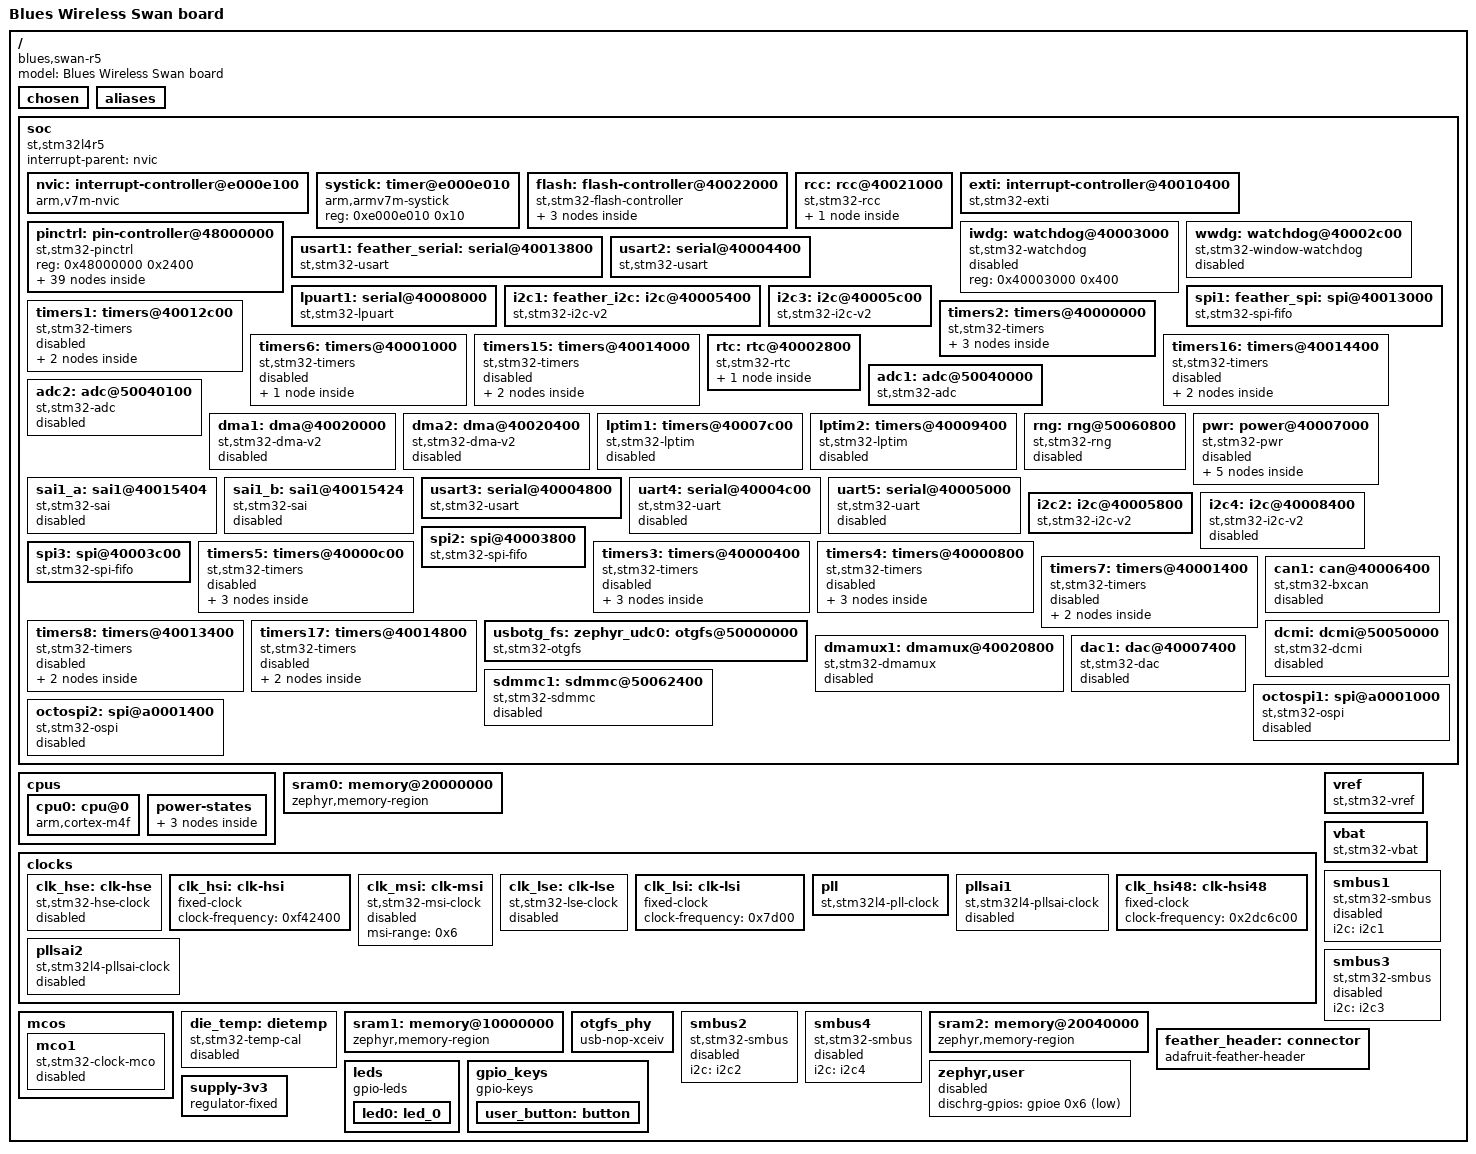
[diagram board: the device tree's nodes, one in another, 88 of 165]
/dts-v1/;

/* node '/' defined in zephyr/dts/common/skeleton.dtsi:9 */
/ {
	#address-cells = < 0x1 >;            /* in zephyr/dts/common/skeleton.dtsi:10 */
	#size-cells = < 0x1 >;               /* in zephyr/dts/common/skeleton.dtsi:11 */
	model = "Blues Wireless Swan board"; /* in zephyr/boards/blues/swan_r5/swan_r5.dts:14 */
	compatible = "blues,swan-r5";        /* in zephyr/boards/blues/swan_r5/swan_r5.dts:15 */

	/* node '/chosen' defined in zephyr/dts/common/skeleton.dtsi:13 */
	chosen {
		zephyr,entropy = &rng;            /* in zephyr/dts/arm/st/l4/stm32l4.dtsi:26 */
		zephyr,flash-controller = &flash; /* in zephyr/dts/arm/st/l4/stm32l4.dtsi:27 */
		zephyr,console = &lpuart1;        /* in zephyr/boards/blues/swan_r5/swan_r5.dts:18 */
		zephyr,shell-uart = &lpuart1;     /* in zephyr/boards/blues/swan_r5/swan_r5.dts:19 */
		zephyr,sram = &sram0;             /* in zephyr/boards/blues/swan_r5/swan_r5.dts:20 */
		zephyr,flash = &flash0;           /* in zephyr/boards/blues/swan_r5/swan_r5.dts:21 */
	};

	/* node '/aliases' defined in zephyr/dts/common/skeleton.dtsi:15 */
	aliases {
		led0 = &led0;         /* in zephyr/boards/blues/swan_r5/swan_r5.dts:57 */
		sw0 = &user_button;   /* in zephyr/boards/blues/swan_r5/swan_r5.dts:58 */
		volt-sensor0 = &vref; /* in zephyr/boards/blues/swan_r5/swan_r5.dts:59 */
		volt-sensor1 = &vbat; /* in zephyr/boards/blues/swan_r5/swan_r5.dts:60 */
	};

	/* node '/soc' defined in zephyr/dts/arm/armv7-m.dtsi:6 */
	soc {
		#address-cells = < 0x1 >;     /* in zephyr/dts/arm/armv7-m.dtsi:7 */
		#size-cells = < 0x1 >;        /* in zephyr/dts/arm/armv7-m.dtsi:8 */
		interrupt-parent = < &nvic >; /* in zephyr/dts/arm/armv7-m.dtsi:10 */
		ranges;                       /* in zephyr/dts/arm/armv7-m.dtsi:11 */
		compatible = "st,stm32l4r5",
		             "st,stm32l4",
		             "simple-bus";    /* in zephyr/dts/arm/st/l4/stm32l4r5.dtsi:29 */

		/* node '/soc/interrupt-controller@e000e100' defined in zephyr/dts/arm/armv7-m.dtsi:13 */
		nvic: interrupt-controller@e000e100 {
			#address-cells = < 0x1 >;            /* in zephyr/dts/arm/armv7-m.dtsi:14 */
			compatible = "arm,v7m-nvic";         /* in zephyr/dts/arm/armv7-m.dtsi:15 */
			reg = < 0xe000e100 0xc00 >;          /* in zephyr/dts/arm/armv7-m.dtsi:16 */
			interrupt-controller;                /* in zephyr/dts/arm/armv7-m.dtsi:17 */
			#interrupt-cells = < 0x2 >;          /* in zephyr/dts/arm/armv7-m.dtsi:18 */
			arm,num-irq-priority-bits = < 0x4 >; /* in zephyr/dts/arm/st/l4/stm32l4.dtsi:596 */
			phandle = < 0x1 >;                   /* in zephyr/dts/arm/armv7-m.dtsi:10 */
		};

		/* node '/soc/timer@e000e010' defined in zephyr/dts/arm/armv7-m.dtsi:21 */
		systick: timer@e000e010 {
			compatible = "arm,armv7m-systick"; /* in zephyr/dts/arm/armv7-m.dtsi:22 */
			reg = < 0xe000e010 0x10 >;         /* in zephyr/dts/arm/armv7-m.dtsi:23 */
		};

		/* node '/soc/flash-controller@40022000' defined in zephyr/dts/arm/st/l4/stm32l4.dtsi:127 */
		flash: flash-controller@40022000 {
			compatible = "st,stm32-flash-controller",
			             "st,stm32l4-flash-controller"; /* in zephyr/dts/arm/st/l4/stm32l4.dtsi:128 */
			reg = < 0x40022000 0x400 >;                 /* in zephyr/dts/arm/st/l4/stm32l4.dtsi:129 */
			interrupts = < 0x4 0x0 >;                   /* in zephyr/dts/arm/st/l4/stm32l4.dtsi:130 */
			clocks = < &rcc 0x48 0x100 >;               /* in zephyr/dts/arm/st/l4/stm32l4.dtsi:131 */
			#address-cells = < 0x1 >;                   /* in zephyr/dts/arm/st/l4/stm32l4.dtsi:133 */
			#size-cells = < 0x1 >;                      /* in zephyr/dts/arm/st/l4/stm32l4.dtsi:134 */

			/* node '/soc/flash-controller@40022000/flash@8000000' defined in zephyr/dts/arm/st/l4/stm32l4.dtsi:136 */
			flash0: flash@8000000 {
				compatible = "st,stm32-nv-flash",
				             "soc-nv-flash";      /* in zephyr/dts/arm/st/l4/stm32l4.dtsi:137 */
				write-block-size = < 0x8 >;       /* in zephyr/dts/arm/st/l4/stm32l4.dtsi:139 */
				max-erase-time = < 0x19 >;        /* in zephyr/dts/arm/st/l4/stm32l4.dtsi:142 */
				erase-block-size = < 0x1000 >;    /* in zephyr/dts/arm/st/l4/stm32l4p5.dtsi:53 */
				reg = < 0x8000000 0x200000 >;     /* in zephyr/dts/arm/st/l4/stm32l4r5Xi.dtsi:14 */

				/* node '/soc/flash-controller@40022000/flash@8000000/partitions' defined in zephyr/boards/blues/swan_r5/swan_r5.dts:185 */
				partitions {
					compatible = "fixed-partitions"; /* in zephyr/boards/blues/swan_r5/swan_r5.dts:186 */
					#address-cells = < 0x1 >;        /* in zephyr/boards/blues/swan_r5/swan_r5.dts:187 */
					#size-cells = < 0x1 >;           /* in zephyr/boards/blues/swan_r5/swan_r5.dts:188 */

					/* node '/soc/flash-controller@40022000/flash@8000000/partitions/partition@1FB000' defined in zephyr/boards/blues/swan_r5/swan_r5.dts:191 */
					storage_partition: partition@1FB000 {
						label = "storage";         /* in zephyr/boards/blues/swan_r5/swan_r5.dts:192 */
						reg = < 0x1fb000 0x4000 >; /* in zephyr/boards/blues/swan_r5/swan_r5.dts:193 */
					};
				};
			};
		};

		/* node '/soc/rcc@40021000' defined in zephyr/dts/arm/st/l4/stm32l4.dtsi:146 */
		rcc: rcc@40021000 {
			compatible = "st,stm32-rcc";     /* in zephyr/dts/arm/st/l4/stm32l4.dtsi:147 */
			#clock-cells = < 0x2 >;          /* in zephyr/dts/arm/st/l4/stm32l4.dtsi:148 */
			reg = < 0x40021000 0x400 >;      /* in zephyr/dts/arm/st/l4/stm32l4.dtsi:149 */
			undershoot-prevention;           /* in zephyr/dts/arm/st/l4/stm32l4p5.dtsi:58 */
			clocks = < &pll >;               /* in zephyr/boards/blues/swan_r5/swan_r5.dts:87 */
			clock-frequency = < 0x4c4b400 >; /* in zephyr/boards/blues/swan_r5/swan_r5.dts:88 */
			ahb-prescaler = < 0x1 >;         /* in zephyr/boards/blues/swan_r5/swan_r5.dts:89 */
			apb1-prescaler = < 0x1 >;        /* in zephyr/boards/blues/swan_r5/swan_r5.dts:90 */
			apb2-prescaler = < 0x1 >;        /* in zephyr/boards/blues/swan_r5/swan_r5.dts:91 */
			phandle = < 0x2 >;               /* in zephyr/dts/arm/st/l4/stm32l4.dtsi:131 */

			/* node '/soc/rcc@40021000/reset-controller' defined in zephyr/dts/arm/st/l4/stm32l4.dtsi:151 */
			rctl: reset-controller {
				compatible = "st,stm32-rcc-rctl"; /* in zephyr/dts/arm/st/l4/stm32l4.dtsi:152 */
				#reset-cells = < 0x1 >;           /* in zephyr/dts/arm/st/l4/stm32l4.dtsi:153 */
				phandle = < 0x4 >;                /* in zephyr/dts/arm/st/l4/stm32l4.dtsi:230 */
			};
		};

		/* node '/soc/interrupt-controller@40010400' defined in zephyr/dts/arm/st/l4/stm32l4.dtsi:157 */
		exti: interrupt-controller@40010400 {
			compatible = "st,stm32-exti";  /* in zephyr/dts/arm/st/l4/stm32l4.dtsi:158 */
			interrupt-controller;          /* in zephyr/dts/arm/st/l4/stm32l4.dtsi:159 */
			#interrupt-cells = < 0x1 >;    /* in zephyr/dts/arm/st/l4/stm32l4.dtsi:160 */
			#address-cells = < 0x0 >;      /* in zephyr/dts/arm/st/l4/stm32l4.dtsi:161 */
			reg = < 0x40010400 0x400 >;    /* in zephyr/dts/arm/st/l4/stm32l4.dtsi:162 */
			clocks = < &rcc 0x60 0x1 >;    /* in zephyr/dts/arm/st/l4/stm32l4.dtsi:163 */
			num-lines = < 0x40 >;          /* in zephyr/dts/arm/st/l4/stm32l4.dtsi:164 */
			interrupts = < 0x6 0x0 >,
			             < 0x7 0x0 >,
			             < 0x8 0x0 >,
			             < 0x9 0x0 >,
			             < 0xa 0x0 >,
			             < 0x17 0x0 >,
			             < 0x28 0x0 >;     /* in zephyr/dts/arm/st/l4/stm32l4.dtsi:165 */
			interrupt-names = "line0",
			                  "line1",
			                  "line2",
			                  "line3",
			                  "line4",
			                  "line5-9",
			                  "line10-15"; /* in zephyr/dts/arm/st/l4/stm32l4.dtsi:167 */
			line-ranges = < 0x0 0x1 >,
			              < 0x1 0x1 >,
			              < 0x2 0x1 >,
			              < 0x3 0x1 >,
			              < 0x4 0x1 >,
			              < 0x5 0x5 >,
			              < 0xa 0x6 >;     /* in zephyr/dts/arm/st/l4/stm32l4.dtsi:169 */
		};

		/* node '/soc/pin-controller@48000000' defined in zephyr/dts/arm/st/l4/stm32l4.dtsi:173 */
		pinctrl: pin-controller@48000000 {
			compatible = "st,stm32-pinctrl"; /* in zephyr/dts/arm/st/l4/stm32l4.dtsi:174 */
			#address-cells = < 0x1 >;        /* in zephyr/dts/arm/st/l4/stm32l4.dtsi:175 */
			#size-cells = < 0x1 >;           /* in zephyr/dts/arm/st/l4/stm32l4.dtsi:176 */
			reg = < 0x48000000 0x2400 >;     /* in zephyr/dts/arm/st/l4/stm32l4p5.dtsi:67 */

			/* node '/soc/pin-controller@48000000/gpio@48000000' defined in zephyr/dts/arm/st/l4/stm32l4.dtsi:179 */
			gpioa: gpio@48000000 {
				compatible = "st,stm32-gpio"; /* in zephyr/dts/arm/st/l4/stm32l4.dtsi:180 */
				gpio-controller;              /* in zephyr/dts/arm/st/l4/stm32l4.dtsi:181 */
				#gpio-cells = < 0x2 >;        /* in zephyr/dts/arm/st/l4/stm32l4.dtsi:182 */
				reg = < 0x48000000 0x400 >;   /* in zephyr/dts/arm/st/l4/stm32l4.dtsi:183 */
				clocks = < &rcc 0x4c 0x1 >;   /* in zephyr/dts/arm/st/l4/stm32l4.dtsi:184 */
				phandle = < 0x12 >;           /* in zephyr/boards/blues/swan_r5/swan_r5.dts:143 */
			};

			/* node '/soc/pin-controller@48000000/gpio@48000400' defined in zephyr/dts/arm/st/l4/stm32l4.dtsi:187 */
			gpiob: gpio@48000400 {
				compatible = "st,stm32-gpio"; /* in zephyr/dts/arm/st/l4/stm32l4.dtsi:188 */
				gpio-controller;              /* in zephyr/dts/arm/st/l4/stm32l4.dtsi:189 */
				#gpio-cells = < 0x2 >;        /* in zephyr/dts/arm/st/l4/stm32l4.dtsi:190 */
				reg = < 0x48000400 0x400 >;   /* in zephyr/dts/arm/st/l4/stm32l4.dtsi:191 */
				clocks = < &rcc 0x4c 0x2 >;   /* in zephyr/dts/arm/st/l4/stm32l4.dtsi:192 */
				phandle = < 0x32 >;           /* in zephyr/boards/blues/swan_r5/feather_connector.dtsi:13 */
			};

			/* node '/soc/pin-controller@48000000/gpio@48000800' defined in zephyr/dts/arm/st/l4/stm32l4.dtsi:195 */
			gpioc: gpio@48000800 {
				compatible = "st,stm32-gpio"; /* in zephyr/dts/arm/st/l4/stm32l4.dtsi:196 */
				gpio-controller;              /* in zephyr/dts/arm/st/l4/stm32l4.dtsi:197 */
				#gpio-cells = < 0x2 >;        /* in zephyr/dts/arm/st/l4/stm32l4.dtsi:198 */
				reg = < 0x48000800 0x400 >;   /* in zephyr/dts/arm/st/l4/stm32l4.dtsi:199 */
				clocks = < &rcc 0x4c 0x4 >;   /* in zephyr/dts/arm/st/l4/stm32l4.dtsi:200 */
				phandle = < 0x15 >;           /* in zephyr/dts/arm/st/l4/stm32l4r5Xi.dtsi:26 */
			};

			/* node '/soc/pin-controller@48000000/gpio@48001c00' defined in zephyr/dts/arm/st/l4/stm32l4.dtsi:203 */
			gpioh: gpio@48001c00 {
				compatible = "st,stm32-gpio"; /* in zephyr/dts/arm/st/l4/stm32l4.dtsi:204 */
				gpio-controller;              /* in zephyr/dts/arm/st/l4/stm32l4.dtsi:205 */
				#gpio-cells = < 0x2 >;        /* in zephyr/dts/arm/st/l4/stm32l4.dtsi:206 */
				reg = < 0x48001c00 0x400 >;   /* in zephyr/dts/arm/st/l4/stm32l4.dtsi:207 */
				clocks = < &rcc 0x4c 0x80 >;  /* in zephyr/dts/arm/st/l4/stm32l4.dtsi:208 */
			};

			/* node '/soc/pin-controller@48000000/gpio@48000c00' defined in zephyr/dts/arm/st/l4/stm32l4p5.dtsi:69 */
			gpiod: gpio@48000c00 {
				compatible = "st,stm32-gpio"; /* in zephyr/dts/arm/st/l4/stm32l4p5.dtsi:70 */
				gpio-controller;              /* in zephyr/dts/arm/st/l4/stm32l4p5.dtsi:71 */
				#gpio-cells = < 0x2 >;        /* in zephyr/dts/arm/st/l4/stm32l4p5.dtsi:72 */
				reg = < 0x48000c00 0x400 >;   /* in zephyr/dts/arm/st/l4/stm32l4p5.dtsi:73 */
				clocks = < &rcc 0x4c 0x8 >;   /* in zephyr/dts/arm/st/l4/stm32l4p5.dtsi:74 */
				phandle = < 0x33 >;           /* in zephyr/boards/blues/swan_r5/feather_connector.dtsi:13 */
			};

			/* node '/soc/pin-controller@48000000/gpio@48001000' defined in zephyr/dts/arm/st/l4/stm32l4p5.dtsi:77 */
			gpioe: gpio@48001000 {
				compatible = "st,stm32-gpio"; /* in zephyr/dts/arm/st/l4/stm32l4p5.dtsi:78 */
				gpio-controller;              /* in zephyr/dts/arm/st/l4/stm32l4p5.dtsi:79 */
				#gpio-cells = < 0x2 >;        /* in zephyr/dts/arm/st/l4/stm32l4p5.dtsi:80 */
				reg = < 0x48001000 0x400 >;   /* in zephyr/dts/arm/st/l4/stm32l4p5.dtsi:81 */
				clocks = < &rcc 0x4c 0x10 >;  /* in zephyr/dts/arm/st/l4/stm32l4p5.dtsi:82 */
				phandle = < 0x16 >;           /* in zephyr/dts/arm/st/l4/stm32l4r5Xi.dtsi:30 */
			};

			/* node '/soc/pin-controller@48000000/gpio@48001400' defined in zephyr/dts/arm/st/l4/stm32l4p5.dtsi:85 */
			gpiof: gpio@48001400 {
				compatible = "st,stm32-gpio"; /* in zephyr/dts/arm/st/l4/stm32l4p5.dtsi:86 */
				gpio-controller;              /* in zephyr/dts/arm/st/l4/stm32l4p5.dtsi:87 */
				#gpio-cells = < 0x2 >;        /* in zephyr/dts/arm/st/l4/stm32l4p5.dtsi:88 */
				reg = < 0x48001400 0x400 >;   /* in zephyr/dts/arm/st/l4/stm32l4p5.dtsi:89 */
				clocks = < &rcc 0x4c 0x20 >;  /* in zephyr/dts/arm/st/l4/stm32l4p5.dtsi:90 */
			};

			/* node '/soc/pin-controller@48000000/gpio@48001800' defined in zephyr/dts/arm/st/l4/stm32l4p5.dtsi:93 */
			gpiog: gpio@48001800 {
				compatible = "st,stm32-gpio"; /* in zephyr/dts/arm/st/l4/stm32l4p5.dtsi:94 */
				gpio-controller;              /* in zephyr/dts/arm/st/l4/stm32l4p5.dtsi:95 */
				#gpio-cells = < 0x2 >;        /* in zephyr/dts/arm/st/l4/stm32l4p5.dtsi:96 */
				reg = < 0x48001800 0x400 >;   /* in zephyr/dts/arm/st/l4/stm32l4p5.dtsi:97 */
				clocks = < &rcc 0x4c 0x40 >;  /* in zephyr/dts/arm/st/l4/stm32l4p5.dtsi:98 */
			};

			/* node '/soc/pin-controller@48000000/gpio@48002000' defined in zephyr/dts/arm/st/l4/stm32l4p5.dtsi:101 */
			gpioi: gpio@48002000 {
				compatible = "st,stm32-gpio"; /* in zephyr/dts/arm/st/l4/stm32l4p5.dtsi:102 */
				gpio-controller;              /* in zephyr/dts/arm/st/l4/stm32l4p5.dtsi:103 */
				#gpio-cells = < 0x2 >;        /* in zephyr/dts/arm/st/l4/stm32l4p5.dtsi:104 */
				reg = < 0x48002000 0x400 >;   /* in zephyr/dts/arm/st/l4/stm32l4p5.dtsi:105 */
				clocks = < &rcc 0x4c 0x100 >; /* in zephyr/dts/arm/st/l4/stm32l4p5.dtsi:106 */
			};

			/* node '/soc/pin-controller@48000000/adc1_in6_pa1' defined in modules/hal/stm32/dts/st/l4/stm32l4r5z(g-i)yx-pinctrl.dtsi:19 */
			adc1_in6_pa1: adc1_in6_pa1 {
				pinmux = < 0x30 >;  /* in modules/hal/stm32/dts/st/l4/stm32l4r5z(g-i)yx-pinctrl.dtsi:20 */
				phandle = < 0x14 >; /* in zephyr/boards/blues/swan_r5/swan_r5.dts:199 */
			};

			/* node '/soc/pin-controller@48000000/i2c1_scl_pb6' defined in modules/hal/stm32/dts/st/l4/stm32l4r5z(g-i)yx-pinctrl.dtsi:1299 */
			i2c1_scl_pb6: i2c1_scl_pb6 {
				pinmux = < 0x2c4 >; /* in modules/hal/stm32/dts/st/l4/stm32l4r5z(g-i)yx-pinctrl.dtsi:1300 */
				bias-pull-up;       /* in modules/hal/stm32/dts/st/l4/stm32l4r5z(g-i)yx-pinctrl.dtsi:1301 */
				drive-open-drain;   /* in modules/hal/stm32/dts/st/l4/stm32l4r5z(g-i)yx-pinctrl.dtsi:1302 */
				phandle = < 0xb >;  /* in zephyr/boards/blues/swan_r5/swan_r5.dts:123 */
			};

			/* node '/soc/pin-controller@48000000/i2c2_scl_pf1' defined in modules/hal/stm32/dts/st/l4/stm32l4r5z(g-i)yx-pinctrl.dtsi:1323 */
			i2c2_scl_pf1: i2c2_scl_pf1 {
				pinmux = < 0xa24 >; /* in modules/hal/stm32/dts/st/l4/stm32l4r5z(g-i)yx-pinctrl.dtsi:1324 */
				bias-pull-up;       /* in modules/hal/stm32/dts/st/l4/stm32l4r5z(g-i)yx-pinctrl.dtsi:1325 */
				drive-open-drain;   /* in modules/hal/stm32/dts/st/l4/stm32l4r5z(g-i)yx-pinctrl.dtsi:1326 */
				phandle = < 0x1a >; /* in zephyr/boards/blues/swan_r5/swan_r5.dts:129 */
			};

			/* node '/soc/pin-controller@48000000/i2c3_scl_pc0' defined in modules/hal/stm32/dts/st/l4/stm32l4r5z(g-i)yx-pinctrl.dtsi:1335 */
			i2c3_scl_pc0: i2c3_scl_pc0 {
				pinmux = < 0x404 >; /* in modules/hal/stm32/dts/st/l4/stm32l4r5z(g-i)yx-pinctrl.dtsi:1336 */
				bias-pull-up;       /* in modules/hal/stm32/dts/st/l4/stm32l4r5z(g-i)yx-pinctrl.dtsi:1337 */
				drive-open-drain;   /* in modules/hal/stm32/dts/st/l4/stm32l4r5z(g-i)yx-pinctrl.dtsi:1338 */
				phandle = < 0xd >;  /* in zephyr/boards/blues/swan_r5/swan_r5.dts:135 */
			};

			/* node '/soc/pin-controller@48000000/i2c1_sda_pb7' defined in modules/hal/stm32/dts/st/l4/stm32l4r5z(g-i)yx-pinctrl.dtsi:1373 */
			i2c1_sda_pb7: i2c1_sda_pb7 {
				pinmux = < 0x2e4 >; /* in modules/hal/stm32/dts/st/l4/stm32l4r5z(g-i)yx-pinctrl.dtsi:1374 */
				bias-pull-up;       /* in modules/hal/stm32/dts/st/l4/stm32l4r5z(g-i)yx-pinctrl.dtsi:1375 */
				drive-open-drain;   /* in modules/hal/stm32/dts/st/l4/stm32l4r5z(g-i)yx-pinctrl.dtsi:1376 */
				phandle = < 0xc >;  /* in zephyr/boards/blues/swan_r5/swan_r5.dts:123 */
			};

			/* node '/soc/pin-controller@48000000/i2c2_sda_pf0' defined in modules/hal/stm32/dts/st/l4/stm32l4r5z(g-i)yx-pinctrl.dtsi:1403 */
			i2c2_sda_pf0: i2c2_sda_pf0 {
				pinmux = < 0xa04 >; /* in modules/hal/stm32/dts/st/l4/stm32l4r5z(g-i)yx-pinctrl.dtsi:1404 */
				bias-pull-up;       /* in modules/hal/stm32/dts/st/l4/stm32l4r5z(g-i)yx-pinctrl.dtsi:1405 */
				drive-open-drain;   /* in modules/hal/stm32/dts/st/l4/stm32l4r5z(g-i)yx-pinctrl.dtsi:1406 */
				phandle = < 0x1b >; /* in zephyr/boards/blues/swan_r5/swan_r5.dts:129 */
			};

			/* node '/soc/pin-controller@48000000/i2c3_sda_pc9' defined in modules/hal/stm32/dts/st/l4/stm32l4r5z(g-i)yx-pinctrl.dtsi:1421 */
			i2c3_sda_pc9: i2c3_sda_pc9 {
				pinmux = < 0x526 >; /* in modules/hal/stm32/dts/st/l4/stm32l4r5z(g-i)yx-pinctrl.dtsi:1422 */
				bias-pull-up;       /* in modules/hal/stm32/dts/st/l4/stm32l4r5z(g-i)yx-pinctrl.dtsi:1423 */
				drive-open-drain;   /* in modules/hal/stm32/dts/st/l4/stm32l4r5z(g-i)yx-pinctrl.dtsi:1424 */
				phandle = < 0xe >;  /* in zephyr/boards/blues/swan_r5/swan_r5.dts:135 */
			};

			/* node '/soc/pin-controller@48000000/spi1_miso_pa6' defined in modules/hal/stm32/dts/st/l4/stm32l4r5z(g-i)yx-pinctrl.dtsi:2152 */
			spi1_miso_pa6: spi1_miso_pa6 {
				pinmux = < 0xc5 >;  /* in modules/hal/stm32/dts/st/l4/stm32l4r5z(g-i)yx-pinctrl.dtsi:2153 */
				bias-pull-down;     /* in modules/hal/stm32/dts/st/l4/stm32l4r5z(g-i)yx-pinctrl.dtsi:2154 */
				phandle = < 0x10 >; /* in zephyr/boards/blues/swan_r5/swan_r5.dts:141 */
			};

			/* node '/soc/pin-controller@48000000/spi2_miso_pb14' defined in modules/hal/stm32/dts/st/l4/stm32l4r5z(g-i)yx-pinctrl.dtsi:2177 */
			spi2_miso_pb14: spi2_miso_pb14 {
				pinmux = < 0x3c5 >; /* in modules/hal/stm32/dts/st/l4/stm32l4r5z(g-i)yx-pinctrl.dtsi:2178 */
				bias-pull-down;     /* in modules/hal/stm32/dts/st/l4/stm32l4r5z(g-i)yx-pinctrl.dtsi:2179 */
				phandle = < 0x1e >; /* in zephyr/boards/blues/swan_r5/swan_r5.dts:148 */
			};

			/* node '/soc/pin-controller@48000000/spi3_miso_pc11' defined in modules/hal/stm32/dts/st/l4/stm32l4r5z(g-i)yx-pinctrl.dtsi:2197 */
			spi3_miso_pc11: spi3_miso_pc11 {
				pinmux = < 0x566 >; /* in modules/hal/stm32/dts/st/l4/stm32l4r5z(g-i)yx-pinctrl.dtsi:2198 */
				bias-pull-down;     /* in modules/hal/stm32/dts/st/l4/stm32l4r5z(g-i)yx-pinctrl.dtsi:2199 */
				phandle = < 0x22 >; /* in zephyr/boards/blues/swan_r5/swan_r5.dts:155 */
			};

			/* node '/soc/pin-controller@48000000/spi1_mosi_pa7' defined in modules/hal/stm32/dts/st/l4/stm32l4r5z(g-i)yx-pinctrl.dtsi:2209 */
			spi1_mosi_pa7: spi1_mosi_pa7 {
				pinmux = < 0xe5 >;  /* in modules/hal/stm32/dts/st/l4/stm32l4r5z(g-i)yx-pinctrl.dtsi:2210 */
				bias-pull-down;     /* in modules/hal/stm32/dts/st/l4/stm32l4r5z(g-i)yx-pinctrl.dtsi:2211 */
				phandle = < 0x11 >; /* in zephyr/boards/blues/swan_r5/swan_r5.dts:141 */
			};

			/* node '/soc/pin-controller@48000000/spi2_mosi_pb15' defined in modules/hal/stm32/dts/st/l4/stm32l4r5z(g-i)yx-pinctrl.dtsi:2234 */
			spi2_mosi_pb15: spi2_mosi_pb15 {
				pinmux = < 0x3e5 >; /* in modules/hal/stm32/dts/st/l4/stm32l4r5z(g-i)yx-pinctrl.dtsi:2235 */
				bias-pull-down;     /* in modules/hal/stm32/dts/st/l4/stm32l4r5z(g-i)yx-pinctrl.dtsi:2236 */
				phandle = < 0x1f >; /* in zephyr/boards/blues/swan_r5/swan_r5.dts:148 */
			};

			/* node '/soc/pin-controller@48000000/spi3_mosi_pc12' defined in modules/hal/stm32/dts/st/l4/stm32l4r5z(g-i)yx-pinctrl.dtsi:2259 */
			spi3_mosi_pc12: spi3_mosi_pc12 {
				pinmux = < 0x586 >; /* in modules/hal/stm32/dts/st/l4/stm32l4r5z(g-i)yx-pinctrl.dtsi:2260 */
				bias-pull-down;     /* in modules/hal/stm32/dts/st/l4/stm32l4r5z(g-i)yx-pinctrl.dtsi:2261 */
				phandle = < 0x23 >; /* in zephyr/boards/blues/swan_r5/swan_r5.dts:155 */
			};

			/* node '/soc/pin-controller@48000000/spi2_nss_pd0' defined in modules/hal/stm32/dts/st/l4/stm32l4r5z(g-i)yx-pinctrl.dtsi:2306 */
			spi2_nss_pd0: spi2_nss_pd0 {
				pinmux = < 0x605 >; /* in modules/hal/stm32/dts/st/l4/stm32l4r5z(g-i)yx-pinctrl.dtsi:2307 */
				bias-pull-up;       /* in modules/hal/stm32/dts/st/l4/stm32l4r5z(g-i)yx-pinctrl.dtsi:2308 */
				phandle = < 0x1c >; /* in zephyr/boards/blues/swan_r5/swan_r5.dts:148 */
			};

			/* node '/soc/pin-controller@48000000/spi3_nss_pa15' defined in modules/hal/stm32/dts/st/l4/stm32l4r5z(g-i)yx-pinctrl.dtsi:2316 */
			spi3_nss_pa15: spi3_nss_pa15 {
				pinmux = < 0x1e6 >; /* in modules/hal/stm32/dts/st/l4/stm32l4r5z(g-i)yx-pinctrl.dtsi:2317 */
				bias-pull-up;       /* in modules/hal/stm32/dts/st/l4/stm32l4r5z(g-i)yx-pinctrl.dtsi:2318 */
				phandle = < 0x20 >; /* in zephyr/boards/blues/swan_r5/swan_r5.dts:155 */
			};

			/* node '/soc/pin-controller@48000000/spi1_sck_pa5' defined in modules/hal/stm32/dts/st/l4/stm32l4r5z(g-i)yx-pinctrl.dtsi:2334 */
			spi1_sck_pa5: spi1_sck_pa5 {
				pinmux = < 0xa5 >;             /* in modules/hal/stm32/dts/st/l4/stm32l4r5z(g-i)yx-pinctrl.dtsi:2335 */
				bias-pull-down;                /* in modules/hal/stm32/dts/st/l4/stm32l4r5z(g-i)yx-pinctrl.dtsi:2336 */
				slew-rate = "very-high-speed"; /* in modules/hal/stm32/dts/st/l4/stm32l4r5z(g-i)yx-pinctrl.dtsi:2337 */
				phandle = < 0xf >;             /* in zephyr/boards/blues/swan_r5/swan_r5.dts:141 */
			};

			/* node '/soc/pin-controller@48000000/spi2_sck_pd1' defined in modules/hal/stm32/dts/st/l4/stm32l4r5z(g-i)yx-pinctrl.dtsi:2376 */
			spi2_sck_pd1: spi2_sck_pd1 {
				pinmux = < 0x625 >;            /* in modules/hal/stm32/dts/st/l4/stm32l4r5z(g-i)yx-pinctrl.dtsi:2377 */
				bias-pull-down;                /* in modules/hal/stm32/dts/st/l4/stm32l4r5z(g-i)yx-pinctrl.dtsi:2378 */
				slew-rate = "very-high-speed"; /* in modules/hal/stm32/dts/st/l4/stm32l4r5z(g-i)yx-pinctrl.dtsi:2379 */
				phandle = < 0x1d >;            /* in zephyr/boards/blues/swan_r5/swan_r5.dts:148 */
			};

			/* node '/soc/pin-controller@48000000/spi3_sck_pc10' defined in modules/hal/stm32/dts/st/l4/stm32l4r5z(g-i)yx-pinctrl.dtsi:2394 */
			spi3_sck_pc10: spi3_sck_pc10 {
				pinmux = < 0x546 >;            /* in modules/hal/stm32/dts/st/l4/stm32l4r5z(g-i)yx-pinctrl.dtsi:2395 */
				bias-pull-down;                /* in modules/hal/stm32/dts/st/l4/stm32l4r5z(g-i)yx-pinctrl.dtsi:2396 */
				slew-rate = "very-high-speed"; /* in modules/hal/stm32/dts/st/l4/stm32l4r5z(g-i)yx-pinctrl.dtsi:2397 */
				phandle = < 0x21 >;            /* in zephyr/boards/blues/swan_r5/swan_r5.dts:155 */
			};

			/* node '/soc/pin-controller@48000000/tim2_ch1_pa0' defined in modules/hal/stm32/dts/st/l4/stm32l4r5z(g-i)yx-pinctrl.dtsi:2534 */
			tim2_ch1_pa0: tim2_ch1_pa0 {
				pinmux = < 0x1 >;   /* in modules/hal/stm32/dts/st/l4/stm32l4r5z(g-i)yx-pinctrl.dtsi:2535 */
				phandle = < 0x13 >; /* in zephyr/boards/blues/swan_r5/swan_r5.dts:173 */
			};

			/* node '/soc/pin-controller@48000000/usart1_rx_pa10' defined in modules/hal/stm32/dts/st/l4/stm32l4r5z(g-i)yx-pinctrl.dtsi:3150 */
			usart1_rx_pa10: usart1_rx_pa10 {
				pinmux = < 0x147 >; /* in modules/hal/stm32/dts/st/l4/stm32l4r5z(g-i)yx-pinctrl.dtsi:3151 */
				phandle = < 0x6 >;  /* in zephyr/boards/blues/swan_r5/swan_r5.dts:95 */
			};

			/* node '/soc/pin-controller@48000000/lpuart1_rx_pg8' defined in modules/hal/stm32/dts/st/l4/stm32l4r5z(g-i)yx-pinctrl.dtsi:3166 */
			lpuart1_rx_pg8: lpuart1_rx_pg8 {
				pinmux = < 0xd08 >; /* in modules/hal/stm32/dts/st/l4/stm32l4r5z(g-i)yx-pinctrl.dtsi:3167 */
				phandle = < 0xa >;  /* in zephyr/boards/blues/swan_r5/swan_r5.dts:116 */
			};

			/* node '/soc/pin-controller@48000000/usart2_rx_pd6' defined in modules/hal/stm32/dts/st/l4/stm32l4r5z(g-i)yx-pinctrl.dtsi:3182 */
			usart2_rx_pd6: usart2_rx_pd6 {
				pinmux = < 0x6c7 >; /* in modules/hal/stm32/dts/st/l4/stm32l4r5z(g-i)yx-pinctrl.dtsi:3183 */
				phandle = < 0x8 >;  /* in zephyr/boards/blues/swan_r5/swan_r5.dts:102 */
			};

			/* node '/soc/pin-controller@48000000/usart3_rx_pb11' defined in modules/hal/stm32/dts/st/l4/stm32l4r5z(g-i)yx-pinctrl.dtsi:3186 */
			usart3_rx_pb11: usart3_rx_pb11 {
				pinmux = < 0x367 >; /* in modules/hal/stm32/dts/st/l4/stm32l4r5z(g-i)yx-pinctrl.dtsi:3187 */
				phandle = < 0x19 >; /* in zephyr/boards/blues/swan_r5/swan_r5.dts:109 */
			};

			/* node '/soc/pin-controller@48000000/usart1_tx_pa9' defined in modules/hal/stm32/dts/st/l4/stm32l4r5z(g-i)yx-pinctrl.dtsi:3221 */
			usart1_tx_pa9: usart1_tx_pa9 {
				pinmux = < 0x127 >; /* in modules/hal/stm32/dts/st/l4/stm32l4r5z(g-i)yx-pinctrl.dtsi:3222 */
				bias-pull-up;       /* in modules/hal/stm32/dts/st/l4/stm32l4r5z(g-i)yx-pinctrl.dtsi:3223 */
				phandle = < 0x5 >;  /* in zephyr/boards/blues/swan_r5/swan_r5.dts:95 */
			};

			/* node '/soc/pin-controller@48000000/lpuart1_tx_pg7' defined in modules/hal/stm32/dts/st/l4/stm32l4r5z(g-i)yx-pinctrl.dtsi:3241 */
			lpuart1_tx_pg7: lpuart1_tx_pg7 {
				pinmux = < 0xce8 >; /* in modules/hal/stm32/dts/st/l4/stm32l4r5z(g-i)yx-pinctrl.dtsi:3242 */
				bias-pull-up;       /* in modules/hal/stm32/dts/st/l4/stm32l4r5z(g-i)yx-pinctrl.dtsi:3243 */
				phandle = < 0x9 >;  /* in zephyr/boards/blues/swan_r5/swan_r5.dts:116 */
			};

			/* node '/soc/pin-controller@48000000/usart2_tx_pa2' defined in modules/hal/stm32/dts/st/l4/stm32l4r5z(g-i)yx-pinctrl.dtsi:3251 */
			usart2_tx_pa2: usart2_tx_pa2 {
				pinmux = < 0x47 >; /* in modules/hal/stm32/dts/st/l4/stm32l4r5z(g-i)yx-pinctrl.dtsi:3252 */
				bias-pull-up;      /* in modules/hal/stm32/dts/st/l4/stm32l4r5z(g-i)yx-pinctrl.dtsi:3253 */
				phandle = < 0x7 >; /* in zephyr/boards/blues/swan_r5/swan_r5.dts:102 */
			};

			/* node '/soc/pin-controller@48000000/usart3_tx_pb10' defined in modules/hal/stm32/dts/st/l4/stm32l4r5z(g-i)yx-pinctrl.dtsi:3261 */
			usart3_tx_pb10: usart3_tx_pb10 {
				pinmux = < 0x347 >; /* in modules/hal/stm32/dts/st/l4/stm32l4r5z(g-i)yx-pinctrl.dtsi:3262 */
				bias-pull-up;       /* in modules/hal/stm32/dts/st/l4/stm32l4r5z(g-i)yx-pinctrl.dtsi:3263 */
				phandle = < 0x18 >; /* in zephyr/boards/blues/swan_r5/swan_r5.dts:109 */
			};

			/* node '/soc/pin-controller@48000000/usb_otg_fs_id_pa10' defined in modules/hal/stm32/dts/st/l4/stm32l4r5z(g-i)yx-pinctrl.dtsi:3306 */
			usb_otg_fs_id_pa10: usb_otg_fs_id_pa10 {
				pinmux = < 0x14a >; /* in modules/hal/stm32/dts/st/l4/stm32l4r5z(g-i)yx-pinctrl.dtsi:3307 */
				phandle = < 0x27 >; /* in zephyr/boards/blues/swan_r5/swan_r5.dts:162 */
			};

			/* node '/soc/pin-controller@48000000/usb_otg_fs_dm_pa11' defined in modules/hal/stm32/dts/st/l4/stm32l4r5z(g-i)yx-pinctrl.dtsi:3310 */
			usb_otg_fs_dm_pa11: usb_otg_fs_dm_pa11 {
				pinmux = < 0x16a >; /* in modules/hal/stm32/dts/st/l4/stm32l4r5z(g-i)yx-pinctrl.dtsi:3311 */
				phandle = < 0x25 >; /* in zephyr/boards/blues/swan_r5/swan_r5.dts:162 */
			};

			/* node '/soc/pin-controller@48000000/usb_otg_fs_dp_pa12' defined in modules/hal/stm32/dts/st/l4/stm32l4r5z(g-i)yx-pinctrl.dtsi:3314 */
			usb_otg_fs_dp_pa12: usb_otg_fs_dp_pa12 {
				pinmux = < 0x18a >; /* in modules/hal/stm32/dts/st/l4/stm32l4r5z(g-i)yx-pinctrl.dtsi:3315 */
				phandle = < 0x26 >; /* in zephyr/boards/blues/swan_r5/swan_r5.dts:162 */
			};
		};

		/* node '/soc/watchdog@40003000' defined in zephyr/dts/arm/st/l4/stm32l4.dtsi:212 */
		iwdg: watchdog@40003000 {
			compatible = "st,stm32-watchdog"; /* in zephyr/dts/arm/st/l4/stm32l4.dtsi:213 */
			reg = < 0x40003000 0x400 >;       /* in zephyr/dts/arm/st/l4/stm32l4.dtsi:214 */
			status = "disabled";              /* in zephyr/dts/arm/st/l4/stm32l4.dtsi:215 */
		};

		/* node '/soc/watchdog@40002c00' defined in zephyr/dts/arm/st/l4/stm32l4.dtsi:218 */
		wwdg: watchdog@40002c00 {
			compatible = "st,stm32-window-watchdog"; /* in zephyr/dts/arm/st/l4/stm32l4.dtsi:219 */
			reg = < 0x40002c00 0x400 >;              /* in zephyr/dts/arm/st/l4/stm32l4.dtsi:220 */
			clocks = < &rcc 0x58 0x800 >;            /* in zephyr/dts/arm/st/l4/stm32l4.dtsi:221 */
			interrupts = < 0x0 0x7 >;                /* in zephyr/dts/arm/st/l4/stm32l4.dtsi:222 */
			status = "disabled";                     /* in zephyr/dts/arm/st/l4/stm32l4.dtsi:223 */
		};

		/* node '/soc/serial@40013800' defined in zephyr/dts/arm/st/l4/stm32l4.dtsi:226 */
		usart1: feather_serial: serial@40013800 {
			compatible = "st,stm32-usart",
			             "st,stm32-uart";                   /* in zephyr/dts/arm/st/l4/stm32l4.dtsi:227 */
			reg = < 0x40013800 0x400 >;                     /* in zephyr/dts/arm/st/l4/stm32l4.dtsi:228 */
			clocks = < &rcc 0x60 0x4000 >;                  /* in zephyr/dts/arm/st/l4/stm32l4.dtsi:229 */
			resets = < &rctl 0x80e >;                       /* in zephyr/dts/arm/st/l4/stm32l4.dtsi:230 */
			interrupts = < 0x25 0x0 >;                      /* in zephyr/dts/arm/st/l4/stm32l4.dtsi:231 */
			pinctrl-0 = < &usart1_tx_pa9 &usart1_rx_pa10 >; /* in zephyr/boards/blues/swan_r5/swan_r5.dts:95 */
			pinctrl-names = "default";                      /* in zephyr/boards/blues/swan_r5/swan_r5.dts:96 */
			current-speed = < 0x1c200 >;                    /* in zephyr/boards/blues/swan_r5/swan_r5.dts:97 */
			status = "okay";                                /* in zephyr/boards/blues/swan_r5/swan_r5.dts:98 */
		};

		/* node '/soc/serial@40004400' defined in zephyr/dts/arm/st/l4/stm32l4.dtsi:235 */
		usart2: serial@40004400 {
			compatible = "st,stm32-usart",
			             "st,stm32-uart";                  /* in zephyr/dts/arm/st/l4/stm32l4.dtsi:236 */
			reg = < 0x40004400 0x400 >;                    /* in zephyr/dts/arm/st/l4/stm32l4.dtsi:237 */
			clocks = < &rcc 0x58 0x20000 >;                /* in zephyr/dts/arm/st/l4/stm32l4.dtsi:238 */
			resets = < &rctl 0x711 >;                      /* in zephyr/dts/arm/st/l4/stm32l4.dtsi:239 */
			interrupts = < 0x26 0x0 >;                     /* in zephyr/dts/arm/st/l4/stm32l4.dtsi:240 */
			pinctrl-0 = < &usart2_tx_pa2 &usart2_rx_pd6 >; /* in zephyr/boards/blues/swan_r5/swan_r5.dts:102 */
			pinctrl-names = "default";                     /* in zephyr/boards/blues/swan_r5/swan_r5.dts:103 */
			current-speed = < 0x1c200 >;                   /* in zephyr/boards/blues/swan_r5/swan_r5.dts:104 */
			status = "okay";                               /* in zephyr/boards/blues/swan_r5/swan_r5.dts:105 */
		};

		/* node '/soc/serial@40008000' defined in zephyr/dts/arm/st/l4/stm32l4.dtsi:244 */
		lpuart1: serial@40008000 {
			compatible = "st,stm32-lpuart",
			             "st,stm32-uart";                    /* in zephyr/dts/arm/st/l4/stm32l4.dtsi:245 */
			reg = < 0x40008000 0x400 >;                      /* in zephyr/dts/arm/st/l4/stm32l4.dtsi:246 */
			clocks = < &rcc 0x5c 0x1 >;                      /* in zephyr/dts/arm/st/l4/stm32l4.dtsi:247 */
			resets = < &rctl 0x780 >;                        /* in zephyr/dts/arm/st/l4/stm32l4.dtsi:248 */
			interrupts = < 0x46 0x0 >;                       /* in zephyr/dts/arm/st/l4/stm32l4.dtsi:249 */
			pinctrl-0 = < &lpuart1_tx_pg7 &lpuart1_rx_pg8 >; /* in zephyr/boards/blues/swan_r5/swan_r5.dts:116 */
			pinctrl-names = "default";                       /* in zephyr/boards/blues/swan_r5/swan_r5.dts:117 */
			current-speed = < 0x1c200 >;                     /* in zephyr/boards/blues/swan_r5/swan_r5.dts:118 */
			status = "okay";                                 /* in zephyr/boards/blues/swan_r5/swan_r5.dts:119 */
		};

		/* node '/soc/i2c@40005400' defined in zephyr/dts/arm/st/l4/stm32l4.dtsi:253 */
		i2c1: feather_i2c: i2c@40005400 {
			compatible = "st,stm32-i2c-v2";              /* in zephyr/dts/arm/st/l4/stm32l4.dtsi:254 */
			clock-frequency = < 0x186a0 >;               /* in zephyr/dts/arm/st/l4/stm32l4.dtsi:255 */
			#address-cells = < 0x1 >;                    /* in zephyr/dts/arm/st/l4/stm32l4.dtsi:256 */
			#size-cells = < 0x0 >;                       /* in zephyr/dts/arm/st/l4/stm32l4.dtsi:257 */
			reg = < 0x40005400 0x400 >;                  /* in zephyr/dts/arm/st/l4/stm32l4.dtsi:258 */
			clocks = < &rcc 0x58 0x200000 >;             /* in zephyr/dts/arm/st/l4/stm32l4.dtsi:259 */
			interrupts = < 0x1f 0x0 >,
			             < 0x20 0x0 >;                   /* in zephyr/dts/arm/st/l4/stm32l4.dtsi:260 */
			interrupt-names = "event",
			                  "error";                   /* in zephyr/dts/arm/st/l4/stm32l4.dtsi:261 */
			pinctrl-0 = < &i2c1_scl_pb6 &i2c1_sda_pb7 >; /* in zephyr/boards/blues/swan_r5/swan_r5.dts:123 */
			pinctrl-names = "default";                   /* in zephyr/boards/blues/swan_r5/swan_r5.dts:124 */
			status = "okay";                             /* in zephyr/boards/blues/swan_r5/swan_r5.dts:125 */
			phandle = < 0x2e >;                          /* in zephyr/dts/arm/st/l4/stm32l4.dtsi:582 */
		};

		/* node '/soc/i2c@40005c00' defined in zephyr/dts/arm/st/l4/stm32l4.dtsi:265 */
		i2c3: i2c@40005c00 {
			compatible = "st,stm32-i2c-v2";              /* in zephyr/dts/arm/st/l4/stm32l4.dtsi:266 */
			clock-frequency = < 0x186a0 >;               /* in zephyr/dts/arm/st/l4/stm32l4.dtsi:267 */
			#address-cells = < 0x1 >;                    /* in zephyr/dts/arm/st/l4/stm32l4.dtsi:268 */
			#size-cells = < 0x0 >;                       /* in zephyr/dts/arm/st/l4/stm32l4.dtsi:269 */
			reg = < 0x40005c00 0x400 >;                  /* in zephyr/dts/arm/st/l4/stm32l4.dtsi:270 */
			clocks = < &rcc 0x58 0x800000 >;             /* in zephyr/dts/arm/st/l4/stm32l4.dtsi:271 */
			interrupts = < 0x48 0x0 >,
			             < 0x49 0x0 >;                   /* in zephyr/dts/arm/st/l4/stm32l4.dtsi:272 */
			interrupt-names = "event",
			                  "error";                   /* in zephyr/dts/arm/st/l4/stm32l4.dtsi:273 */
			pinctrl-0 = < &i2c3_scl_pc0 &i2c3_sda_pc9 >; /* in zephyr/boards/blues/swan_r5/swan_r5.dts:135 */
			pinctrl-names = "default";                   /* in zephyr/boards/blues/swan_r5/swan_r5.dts:136 */
			status = "okay";                             /* in zephyr/boards/blues/swan_r5/swan_r5.dts:137 */
			phandle = < 0x2f >;                          /* in zephyr/dts/arm/st/l4/stm32l4.dtsi:590 */
		};

		/* node '/soc/spi@40013000' defined in zephyr/dts/arm/st/l4/stm32l4.dtsi:287 */
		spi1: feather_spi: spi@40013000 {
			compatible = "st,stm32-spi-fifo",
			             "st,stm32-spi";                                 /* in zephyr/dts/arm/st/l4/stm32l4.dtsi:288 */
			#address-cells = < 0x1 >;                                    /* in zephyr/dts/arm/st/l4/stm32l4.dtsi:289 */
			#size-cells = < 0x0 >;                                       /* in zephyr/dts/arm/st/l4/stm32l4.dtsi:290 */
			reg = < 0x40013000 0x400 >;                                  /* in zephyr/dts/arm/st/l4/stm32l4.dtsi:291 */
			interrupts = < 0x23 0x5 >;                                   /* in zephyr/dts/arm/st/l4/stm32l4.dtsi:292 */
			clocks = < &rcc 0x60 0x1000 >;                               /* in zephyr/dts/arm/st/l4/stm32l4.dtsi:293 */
			pinctrl-0 = < &spi1_sck_pa5 &spi1_miso_pa6 &spi1_mosi_pa7 >; /* in zephyr/boards/blues/swan_r5/swan_r5.dts:141 */
			pinctrl-names = "default";                                   /* in zephyr/boards/blues/swan_r5/swan_r5.dts:142 */
			cs-gpios = < &gpioa 0x4 0x11 >;                              /* in zephyr/boards/blues/swan_r5/swan_r5.dts:143 */
			status = "okay";                                             /* in zephyr/boards/blues/swan_r5/swan_r5.dts:144 */
		};

		/* node '/soc/timers@40012c00' defined in zephyr/dts/arm/st/l4/stm32l4.dtsi:297 */
		timers1: timers@40012c00 {
			compatible = "st,stm32-timers"; /* in zephyr/dts/arm/st/l4/stm32l4.dtsi:298 */
			reg = < 0x40012c00 0x400 >;     /* in zephyr/dts/arm/st/l4/stm32l4.dtsi:299 */
			clocks = < &rcc 0x60 0x800 >,
			         < &rcc 0x9 0xff >;     /* in zephyr/dts/arm/st/l4/stm32l4.dtsi:300 */
			resets = < &rctl 0x80b >;       /* in zephyr/dts/arm/st/l4/stm32l4.dtsi:302 */
			interrupts = < 0x18 0x0 >,
			             < 0x19 0x0 >,
			             < 0x1a 0x0 >,
			             < 0x1b 0x0 >;      /* in zephyr/dts/arm/st/l4/stm32l4.dtsi:303 */
			interrupt-names = "brk",
			                  "up",
			                  "trgcom",
			                  "cc";         /* in zephyr/dts/arm/st/l4/stm32l4.dtsi:304 */
			st,prescaler = < 0x0 >;         /* in zephyr/dts/arm/st/l4/stm32l4.dtsi:305 */
			status = "disabled";            /* in zephyr/dts/arm/st/l4/stm32l4.dtsi:306 */

			/* node '/soc/timers@40012c00/pwm' defined in zephyr/dts/arm/st/l4/stm32l4.dtsi:308 */
			pwm {
				compatible = "st,stm32-pwm"; /* in zephyr/dts/arm/st/l4/stm32l4.dtsi:309 */
				status = "disabled";         /* in zephyr/dts/arm/st/l4/stm32l4.dtsi:310 */
				#pwm-cells = < 0x3 >;        /* in zephyr/dts/arm/st/l4/stm32l4.dtsi:311 */
			};

			/* node '/soc/timers@40012c00/qdec' defined in zephyr/dts/arm/st/l4/stm32l4.dtsi:314 */
			qdec {
				compatible = "st,stm32-qdec";    /* in zephyr/dts/arm/st/l4/stm32l4.dtsi:315 */
				st,input-filter-level = < 0x0 >; /* in zephyr/dts/arm/st/l4/stm32l4.dtsi:316 */
				status = "disabled";             /* in zephyr/dts/arm/st/l4/stm32l4.dtsi:317 */
			};
		};

		/* node '/soc/timers@40000000' defined in zephyr/dts/arm/st/l4/stm32l4.dtsi:321 */
		timers2: timers@40000000 {
			compatible = "st,stm32-timers"; /* in zephyr/dts/arm/st/l4/stm32l4.dtsi:322 */
			reg = < 0x40000000 0x400 >;     /* in zephyr/dts/arm/st/l4/stm32l4.dtsi:323 */
			clocks = < &rcc 0x58 0x1 >,
			         < &rcc 0x8 0xff >;     /* in zephyr/dts/arm/st/l4/stm32l4.dtsi:324 */
			resets = < &rctl 0x700 >;       /* in zephyr/dts/arm/st/l4/stm32l4.dtsi:326 */
			interrupts = < 0x1c 0x0 >;      /* in zephyr/dts/arm/st/l4/stm32l4.dtsi:327 */
			interrupt-names = "global";     /* in zephyr/dts/arm/st/l4/stm32l4.dtsi:328 */
			st,prescaler = < 0x0 >;         /* in zephyr/dts/arm/st/l4/stm32l4.dtsi:329 */
			status = "okay";                /* in zephyr/boards/blues/swan_r5/swan_r5.dts:169 */

			/* node '/soc/timers@40000000/pwm' defined in zephyr/dts/arm/st/l4/stm32l4.dtsi:332 */
			pwm2: pwm {
				compatible = "st,stm32-pwm";   /* in zephyr/dts/arm/st/l4/stm32l4.dtsi:333 */
				#pwm-cells = < 0x3 >;          /* in zephyr/dts/arm/st/l4/stm32l4.dtsi:335 */
				status = "okay";               /* in zephyr/boards/blues/swan_r5/swan_r5.dts:172 */
				pinctrl-0 = < &tim2_ch1_pa0 >; /* in zephyr/boards/blues/swan_r5/swan_r5.dts:173 */
				pinctrl-names = "default";     /* in zephyr/boards/blues/swan_r5/swan_r5.dts:174 */
			};

			/* node '/soc/timers@40000000/counter' defined in zephyr/dts/arm/st/l4/stm32l4.dtsi:338 */
			counter {
				compatible = "st,stm32-counter"; /* in zephyr/dts/arm/st/l4/stm32l4.dtsi:339 */
				status = "disabled";             /* in zephyr/dts/arm/st/l4/stm32l4.dtsi:340 */
			};

			/* node '/soc/timers@40000000/qdec' defined in zephyr/dts/arm/st/l4/stm32l4.dtsi:343 */
			qdec {
				compatible = "st,stm32-qdec";    /* in zephyr/dts/arm/st/l4/stm32l4.dtsi:344 */
				st,input-filter-level = < 0x0 >; /* in zephyr/dts/arm/st/l4/stm32l4.dtsi:345 */
				status = "disabled";             /* in zephyr/dts/arm/st/l4/stm32l4.dtsi:346 */
			};
		};

		/* node '/soc/timers@40001000' defined in zephyr/dts/arm/st/l4/stm32l4.dtsi:350 */
		timers6: timers@40001000 {
			compatible = "st,stm32-timers"; /* in zephyr/dts/arm/st/l4/stm32l4.dtsi:351 */
			reg = < 0x40001000 0x400 >;     /* in zephyr/dts/arm/st/l4/stm32l4.dtsi:352 */
			clocks = < &rcc 0x58 0x10 >,
			         < &rcc 0x8 0xff >;     /* in zephyr/dts/arm/st/l4/stm32l4.dtsi:353 */
			resets = < &rctl 0x704 >;       /* in zephyr/dts/arm/st/l4/stm32l4.dtsi:355 */
			interrupts = < 0x36 0x0 >;      /* in zephyr/dts/arm/st/l4/stm32l4.dtsi:356 */
			interrupt-names = "global";     /* in zephyr/dts/arm/st/l4/stm32l4.dtsi:357 */
			st,prescaler = < 0x0 >;         /* in zephyr/dts/arm/st/l4/stm32l4.dtsi:358 */
			status = "disabled";            /* in zephyr/dts/arm/st/l4/stm32l4.dtsi:359 */

			/* node '/soc/timers@40001000/counter' defined in zephyr/dts/arm/st/l4/stm32l4.dtsi:361 */
			counter {
				compatible = "st,stm32-counter"; /* in zephyr/dts/arm/st/l4/stm32l4.dtsi:362 */
				status = "disabled";             /* in zephyr/dts/arm/st/l4/stm32l4.dtsi:363 */
			};
		};

		/* node '/soc/timers@40014000' defined in zephyr/dts/arm/st/l4/stm32l4.dtsi:367 */
		timers15: timers@40014000 {
			compatible = "st,stm32-timers"; /* in zephyr/dts/arm/st/l4/stm32l4.dtsi:368 */
			reg = < 0x40014000 0x400 >;     /* in zephyr/dts/arm/st/l4/stm32l4.dtsi:369 */
			clocks = < &rcc 0x60 0x10000 >,
			         < &rcc 0x9 0xff >;     /* in zephyr/dts/arm/st/l4/stm32l4.dtsi:370 */
			resets = < &rctl 0x810 >;       /* in zephyr/dts/arm/st/l4/stm32l4.dtsi:372 */
			interrupts = < 0x18 0x0 >;      /* in zephyr/dts/arm/st/l4/stm32l4.dtsi:373 */
			interrupt-names = "global";     /* in zephyr/dts/arm/st/l4/stm32l4.dtsi:374 */
			st,prescaler = < 0x0 >;         /* in zephyr/dts/arm/st/l4/stm32l4.dtsi:375 */
			status = "disabled";            /* in zephyr/dts/arm/st/l4/stm32l4.dtsi:376 */

			/* node '/soc/timers@40014000/pwm' defined in zephyr/dts/arm/st/l4/stm32l4.dtsi:378 */
			pwm {
				compatible = "st,stm32-pwm"; /* in zephyr/dts/arm/st/l4/stm32l4.dtsi:379 */
				status = "disabled";         /* in zephyr/dts/arm/st/l4/stm32l4.dtsi:380 */
				#pwm-cells = < 0x3 >;        /* in zephyr/dts/arm/st/l4/stm32l4.dtsi:381 */
			};

			/* node '/soc/timers@40014000/counter' defined in zephyr/dts/arm/st/l4/stm32l4.dtsi:384 */
			counter {
				compatible = "st,stm32-counter"; /* in zephyr/dts/arm/st/l4/stm32l4.dtsi:385 */
				status = "disabled";             /* in zephyr/dts/arm/st/l4/stm32l4.dtsi:386 */
			};
		};

		/* node '/soc/timers@40014400' defined in zephyr/dts/arm/st/l4/stm32l4.dtsi:390 */
		timers16: timers@40014400 {
			compatible = "st,stm32-timers"; /* in zephyr/dts/arm/st/l4/stm32l4.dtsi:391 */
			reg = < 0x40014400 0x400 >;     /* in zephyr/dts/arm/st/l4/stm32l4.dtsi:392 */
			clocks = < &rcc 0x60 0x20000 >,
			         < &rcc 0x9 0xff >;     /* in zephyr/dts/arm/st/l4/stm32l4.dtsi:393 */
			resets = < &rctl 0x811 >;       /* in zephyr/dts/arm/st/l4/stm32l4.dtsi:395 */
			interrupts = < 0x19 0x0 >;      /* in zephyr/dts/arm/st/l4/stm32l4.dtsi:396 */
			interrupt-names = "global";     /* in zephyr/dts/arm/st/l4/stm32l4.dtsi:397 */
			st,prescaler = < 0x0 >;         /* in zephyr/dts/arm/st/l4/stm32l4.dtsi:398 */
			status = "disabled";            /* in zephyr/dts/arm/st/l4/stm32l4.dtsi:399 */

			/* node '/soc/timers@40014400/pwm' defined in zephyr/dts/arm/st/l4/stm32l4.dtsi:401 */
			pwm {
				compatible = "st,stm32-pwm"; /* in zephyr/dts/arm/st/l4/stm32l4.dtsi:402 */
				status = "disabled";         /* in zephyr/dts/arm/st/l4/stm32l4.dtsi:403 */
				#pwm-cells = < 0x3 >;        /* in zephyr/dts/arm/st/l4/stm32l4.dtsi:404 */
			};

			/* node '/soc/timers@40014400/counter' defined in zephyr/dts/arm/st/l4/stm32l4.dtsi:407 */
			counter {
				compatible = "st,stm32-counter"; /* in zephyr/dts/arm/st/l4/stm32l4.dtsi:408 */
				status = "disabled";             /* in zephyr/dts/arm/st/l4/stm32l4.dtsi:409 */
			};
		};

		/* node '/soc/rtc@40002800' defined in zephyr/dts/arm/st/l4/stm32l4.dtsi:413 */
		rtc: rtc@40002800 {
			compatible = "st,stm32-rtc";       /* in zephyr/dts/arm/st/l4/stm32l4.dtsi:414 */
			reg = < 0x40002800 0x400 >;        /* in zephyr/dts/arm/st/l4/stm32l4.dtsi:415 */
			interrupts = < 0x29 0x0 >;         /* in zephyr/dts/arm/st/l4/stm32l4.dtsi:416 */
			prescaler = < 0x8000 >;            /* in zephyr/dts/arm/st/l4/stm32l4.dtsi:418 */
			alarms-count = < 0x2 >;            /* in zephyr/dts/arm/st/l4/stm32l4.dtsi:419 */
			alrm-exti-line = < 0x12 >;         /* in zephyr/dts/arm/st/l4/stm32l4.dtsi:420 */
			clocks = < &rcc 0x58 0x10000000 >,
			         < &rcc 0x3 0x2280090 >;   /* in zephyr/boards/blues/swan_r5/swan_r5.dts:179 */
			status = "okay";                   /* in zephyr/boards/blues/swan_r5/swan_r5.dts:181 */

			/* node '/soc/rtc@40002800/backup_regs' defined in zephyr/dts/arm/st/l4/stm32l4r5.dtsi:32 */
			bbram: backup_regs {
				compatible = "st,stm32-bbram"; /* in zephyr/dts/arm/st/l4/stm32l4r5.dtsi:33 */
				st,backup-regs = < 0x20 >;     /* in zephyr/dts/arm/st/l4/stm32l4r5.dtsi:34 */
				status = "disabled";           /* in zephyr/dts/arm/st/l4/stm32l4r5.dtsi:35 */
			};
		};

		/* node '/soc/adc@50040000' defined in zephyr/dts/arm/st/l4/stm32l4.dtsi:424 */
		adc1: adc@50040000 {
			compatible = "st,stm32-adc";                                /* in zephyr/dts/arm/st/l4/stm32l4.dtsi:425 */
			reg = < 0x50040000 0x100 >;                                 /* in zephyr/dts/arm/st/l4/stm32l4.dtsi:426 */
			clocks = < &rcc 0x4c 0x2000 >;                              /* in zephyr/dts/arm/st/l4/stm32l4.dtsi:427 */
			clock-names = "adcx";                                       /* in zephyr/dts/arm/st/l4/stm32l4.dtsi:428 */
			interrupts = < 0x12 0x0 >;                                  /* in zephyr/dts/arm/st/l4/stm32l4.dtsi:429 */
			#io-channel-cells = < 0x1 >;                                /* in zephyr/dts/arm/st/l4/stm32l4.dtsi:430 */
			resolutions = < 0x60630c 0x51630c 0x42630c 0x33630c >;      /* in zephyr/dts/arm/st/l4/stm32l4.dtsi:431 */
			sampling-times = < 0x3 0x7 0xd 0x19 0x30 0x5d 0xf8 0x281 >; /* in zephyr/dts/arm/st/l4/stm32l4.dtsi:435 */
			st,adc-sequencer = "programmable";                          /* in zephyr/dts/arm/st/l4/stm32l4.dtsi:436 */
			st,adc-oversampler = "minimal";                             /* in zephyr/dts/arm/st/l4/stm32l4.dtsi:437 */
			st,adc-internal-regulator = "startup-sw-delay";             /* in zephyr/dts/arm/st/l4/stm32l4.dtsi:438 */
			st,adc-has-deep-powerdown;                                  /* in zephyr/dts/arm/st/l4/stm32l4.dtsi:439 */
			st,adc-has-differential-support;                            /* in zephyr/dts/arm/st/l4/stm32l4.dtsi:440 */
			pinctrl-0 = < &adc1_in6_pa1 >;                              /* in zephyr/boards/blues/swan_r5/swan_r5.dts:199 */
			pinctrl-names = "default";                                  /* in zephyr/boards/blues/swan_r5/swan_r5.dts:200 */
			st,adc-clock-source = "SYNC";                               /* in zephyr/boards/blues/swan_r5/swan_r5.dts:201 */
			st,adc-prescaler = < 0x4 >;                                 /* in zephyr/boards/blues/swan_r5/swan_r5.dts:202 */
			status = "okay";                                            /* in zephyr/boards/blues/swan_r5/swan_r5.dts:203 */
			phandle = < 0x2d >;                                         /* in zephyr/dts/arm/st/l4/stm32l4.dtsi:559 */
		};

		/* node '/soc/adc@50040100' defined in zephyr/dts/arm/st/l4/stm32l4.dtsi:444 */
		adc2: adc@50040100 {
			compatible = "st,stm32-adc";                                /* in zephyr/dts/arm/st/l4/stm32l4.dtsi:445 */
			reg = < 0x50040100 0x100 >;                                 /* in zephyr/dts/arm/st/l4/stm32l4.dtsi:446 */
			clocks = < &rcc 0x4c 0x2000 >;                              /* in zephyr/dts/arm/st/l4/stm32l4.dtsi:447 */
			clock-names = "adcx";                                       /* in zephyr/dts/arm/st/l4/stm32l4.dtsi:448 */
			interrupts = < 0x12 0x0 >;                                  /* in zephyr/dts/arm/st/l4/stm32l4.dtsi:449 */
			#io-channel-cells = < 0x1 >;                                /* in zephyr/dts/arm/st/l4/stm32l4.dtsi:450 */
			resolutions = < 0x60630c 0x51630c 0x42630c 0x33630c >;      /* in zephyr/dts/arm/st/l4/stm32l4.dtsi:451 */
			sampling-times = < 0x3 0x7 0xd 0x19 0x30 0x5d 0xf8 0x281 >; /* in zephyr/dts/arm/st/l4/stm32l4.dtsi:455 */
			st,adc-sequencer = "programmable";                          /* in zephyr/dts/arm/st/l4/stm32l4.dtsi:456 */
			st,adc-oversampler = "minimal";                             /* in zephyr/dts/arm/st/l4/stm32l4.dtsi:457 */
			st,adc-internal-regulator = "startup-sw-delay";             /* in zephyr/dts/arm/st/l4/stm32l4.dtsi:458 */
			st,adc-has-deep-powerdown;                                  /* in zephyr/dts/arm/st/l4/stm32l4.dtsi:459 */
			st,adc-has-differential-support;                            /* in zephyr/dts/arm/st/l4/stm32l4.dtsi:460 */
			status = "disabled";                                        /* in zephyr/dts/arm/st/l4/stm32l4.dtsi:461 */
		};

		/* node '/soc/dma@40020000' defined in zephyr/dts/arm/st/l4/stm32l4.dtsi:464 */
		dma1: dma@40020000 {
			compatible = "st,stm32-dma-v2";                                             /* in zephyr/dts/arm/st/l4/stm32l4.dtsi:465 */
			#dma-cells = < 0x3 >;                                                       /* in zephyr/dts/arm/st/l4/stm32l4.dtsi:466 */
			reg = < 0x40020000 0x400 >;                                                 /* in zephyr/dts/arm/st/l4/stm32l4.dtsi:467 */
			interrupts = < 0xb 0x0 0xc 0x0 0xd 0x0 0xe 0x0 0xf 0x0 0x10 0x0 0x11 0x0 >; /* in zephyr/dts/arm/st/l4/stm32l4.dtsi:468 */
			clocks = < &rcc 0x48 0x1 >;                                                 /* in zephyr/dts/arm/st/l4/stm32l4.dtsi:469 */
			dma-requests = < 0x7 >;                                                     /* in zephyr/dts/arm/st/l4/stm32l4.dtsi:470 */
			status = "disabled";                                                        /* in zephyr/dts/arm/st/l4/stm32l4.dtsi:471 */
			dma-offset = < 0x0 >;                                                       /* in zephyr/dts/arm/st/l4/stm32l4p5.dtsi:362 */
			phandle = < 0x28 >;                                                         /* in zephyr/dts/arm/st/l4/stm32l4r5.dtsi:40 */
		};

		/* node '/soc/dma@40020400' defined in zephyr/dts/arm/st/l4/stm32l4.dtsi:474 */
		dma2: dma@40020400 {
			compatible = "st,stm32-dma-v2";                                                  /* in zephyr/dts/arm/st/l4/stm32l4.dtsi:475 */
			#dma-cells = < 0x3 >;                                                            /* in zephyr/dts/arm/st/l4/stm32l4.dtsi:476 */
			reg = < 0x40020400 0x400 >;                                                      /* in zephyr/dts/arm/st/l4/stm32l4.dtsi:477 */
			interrupts = < 0x38 0x0 0x39 0x0 0x3a 0x0 0x3b 0x0 0x3c 0x0 0x44 0x0 0x45 0x0 >; /* in zephyr/dts/arm/st/l4/stm32l4.dtsi:478 */
			clocks = < &rcc 0x48 0x2 >;                                                      /* in zephyr/dts/arm/st/l4/stm32l4.dtsi:479 */
			dma-requests = < 0x7 >;                                                          /* in zephyr/dts/arm/st/l4/stm32l4.dtsi:480 */
			status = "disabled";                                                             /* in zephyr/dts/arm/st/l4/stm32l4.dtsi:481 */
			dma-offset = < 0x7 >;                                                            /* in zephyr/dts/arm/st/l4/stm32l4p5.dtsi:366 */
			phandle = < 0x17 >;                                                              /* in zephyr/dts/arm/st/l4/stm32l4_sai.dtsi:16 */
		};

		/* node '/soc/timers@40007c00' defined in zephyr/dts/arm/st/l4/stm32l4.dtsi:484 */
		lptim1: timers@40007c00 {
			compatible = "st,stm32-lptim";     /* in zephyr/dts/arm/st/l4/stm32l4.dtsi:485 */
			clocks = < &rcc 0x58 0x80000000 >; /* in zephyr/dts/arm/st/l4/stm32l4.dtsi:486 */
			#address-cells = < 0x1 >;          /* in zephyr/dts/arm/st/l4/stm32l4.dtsi:487 */
			#size-cells = < 0x0 >;             /* in zephyr/dts/arm/st/l4/stm32l4.dtsi:488 */
			reg = < 0x40007c00 0x400 >;        /* in zephyr/dts/arm/st/l4/stm32l4.dtsi:489 */
			interrupts = < 0x41 0x1 >;         /* in zephyr/dts/arm/st/l4/stm32l4.dtsi:490 */
			interrupt-names = "wakeup";        /* in zephyr/dts/arm/st/l4/stm32l4.dtsi:491 */
			status = "disabled";               /* in zephyr/dts/arm/st/l4/stm32l4.dtsi:492 */
		};

		/* node '/soc/timers@40009400' defined in zephyr/dts/arm/st/l4/stm32l4.dtsi:495 */
		lptim2: timers@40009400 {
			compatible = "st,stm32-lptim"; /* in zephyr/dts/arm/st/l4/stm32l4.dtsi:496 */
			#address-cells = < 0x1 >;      /* in zephyr/dts/arm/st/l4/stm32l4.dtsi:497 */
			#size-cells = < 0x0 >;         /* in zephyr/dts/arm/st/l4/stm32l4.dtsi:498 */
			reg = < 0x40009400 0x400 >;    /* in zephyr/dts/arm/st/l4/stm32l4.dtsi:499 */
			clocks = < &rcc 0x5c 0x20 >;   /* in zephyr/dts/arm/st/l4/stm32l4.dtsi:500 */
			interrupts = < 0x42 0x1 >;     /* in zephyr/dts/arm/st/l4/stm32l4.dtsi:501 */
			interrupt-names = "wakeup";    /* in zephyr/dts/arm/st/l4/stm32l4.dtsi:502 */
			status = "disabled";           /* in zephyr/dts/arm/st/l4/stm32l4.dtsi:503 */
		};

		/* node '/soc/rng@50060800' defined in zephyr/dts/arm/st/l4/stm32l4.dtsi:506 */
		rng: rng@50060800 {
			compatible = "st,stm32-rng";    /* in zephyr/dts/arm/st/l4/stm32l4.dtsi:507 */
			reg = < 0x50060800 0x400 >;     /* in zephyr/dts/arm/st/l4/stm32l4.dtsi:508 */
			interrupts = < 0x50 0x0 >;      /* in zephyr/dts/arm/st/l4/stm32l4.dtsi:509 */
			status = "disabled";            /* in zephyr/dts/arm/st/l4/stm32l4.dtsi:515 */
			clocks = < &rcc 0x4c 0x40000 >,
			         < &rcc 0x5 0x3a0088 >; /* in zephyr/dts/arm/st/l4/stm32l4p5.dtsi:62 */
		};

		/* node '/soc/power@40007000' defined in zephyr/dts/arm/st/l4/stm32l4.dtsi:518 */
		pwr: power@40007000 {
			compatible = "st,stm32-pwr"; /* in zephyr/dts/arm/st/l4/stm32l4.dtsi:519 */
			reg = < 0x40007000 0x400 >;  /* in zephyr/dts/arm/st/l4/stm32l4.dtsi:520 */
			status = "disabled";         /* in zephyr/dts/arm/st/l4/stm32l4.dtsi:521 */
			wkup-pins-nb = < 0x5 >;      /* in zephyr/dts/arm/st/l4/stm32l4.dtsi:523 */
			wkup-pins-pol;               /* in zephyr/dts/arm/st/l4/stm32l4.dtsi:524 */
			wkup-pins-pupd;              /* in zephyr/dts/arm/st/l4/stm32l4.dtsi:525 */
			#address-cells = < 0x1 >;    /* in zephyr/dts/arm/st/l4/stm32l4.dtsi:527 */
			#size-cells = < 0x0 >;       /* in zephyr/dts/arm/st/l4/stm32l4.dtsi:528 */

			/* node '/soc/power@40007000/wkup-pin@1' defined in zephyr/dts/arm/st/l4/stm32l4.dtsi:530 */
			wkup-pin@1 {
				reg = < 0x1 >;                   /* in zephyr/dts/arm/st/l4/stm32l4.dtsi:531 */
				wkup-gpios = < &gpioa 0x0 0x1 >; /* in zephyr/dts/arm/st/l4/stm32l4r5Xi.dtsi:22 */
			};

			/* node '/soc/power@40007000/wkup-pin@2' defined in zephyr/dts/arm/st/l4/stm32l4.dtsi:534 */
			wkup-pin@2 {
				reg = < 0x2 >;                   /* in zephyr/dts/arm/st/l4/stm32l4.dtsi:535 */
				wkup-gpios = < &gpioc 0xd 0x1 >; /* in zephyr/dts/arm/st/l4/stm32l4r5Xi.dtsi:26 */
			};

			/* node '/soc/power@40007000/wkup-pin@3' defined in zephyr/dts/arm/st/l4/stm32l4.dtsi:538 */
			wkup-pin@3 {
				reg = < 0x3 >;                   /* in zephyr/dts/arm/st/l4/stm32l4.dtsi:539 */
				wkup-gpios = < &gpioe 0x6 0x1 >; /* in zephyr/dts/arm/st/l4/stm32l4r5Xi.dtsi:30 */
			};

			/* node '/soc/power@40007000/wkup-pin@4' defined in zephyr/dts/arm/st/l4/stm32l4.dtsi:542 */
			wkup-pin@4 {
				reg = < 0x4 >;                   /* in zephyr/dts/arm/st/l4/stm32l4.dtsi:543 */
				wkup-gpios = < &gpioa 0x2 0x1 >; /* in zephyr/dts/arm/st/l4/stm32l4r5Xi.dtsi:34 */
			};

			/* node '/soc/power@40007000/wkup-pin@5' defined in zephyr/dts/arm/st/l4/stm32l4.dtsi:546 */
			wkup-pin@5 {
				reg = < 0x5 >;                   /* in zephyr/dts/arm/st/l4/stm32l4.dtsi:547 */
				wkup-gpios = < &gpioc 0x5 0x1 >; /* in zephyr/dts/arm/st/l4/stm32l4r5Xi.dtsi:38 */
			};
		};

		/* node '/soc/sai1@40015404' defined in zephyr/dts/arm/st/l4/stm32l4_sai.dtsi:9 */
		sai1_a: sai1@40015404 {
			compatible = "st,stm32-sai";      /* in zephyr/dts/arm/st/l4/stm32l4_sai.dtsi:10 */
			#address-cells = < 0x1 >;         /* in zephyr/dts/arm/st/l4/stm32l4_sai.dtsi:11 */
			#size-cells = < 0x0 >;            /* in zephyr/dts/arm/st/l4/stm32l4_sai.dtsi:12 */
			reg = < 0x40015404 0x20 >;        /* in zephyr/dts/arm/st/l4/stm32l4_sai.dtsi:13 */
			clocks = < &rcc 0x60 0x200000 >,
			         < &rcc 0xd 0x360088 >;   /* in zephyr/dts/arm/st/l4/stm32l4_sai.dtsi:14 */
			dmas = < &dma2 0x1 0x1 0x22800 >; /* in zephyr/dts/arm/st/l4/stm32l4_sai.dtsi:16 */
			status = "disabled";              /* in zephyr/dts/arm/st/l4/stm32l4_sai.dtsi:18 */
		};

		/* node '/soc/sai1@40015424' defined in zephyr/dts/arm/st/l4/stm32l4_sai.dtsi:21 */
		sai1_b: sai1@40015424 {
			compatible = "st,stm32-sai";      /* in zephyr/dts/arm/st/l4/stm32l4_sai.dtsi:22 */
			#address-cells = < 0x1 >;         /* in zephyr/dts/arm/st/l4/stm32l4_sai.dtsi:23 */
			#size-cells = < 0x0 >;            /* in zephyr/dts/arm/st/l4/stm32l4_sai.dtsi:24 */
			reg = < 0x40015424 0x20 >;        /* in zephyr/dts/arm/st/l4/stm32l4_sai.dtsi:25 */
			clocks = < &rcc 0x60 0x200000 >,
			         < &rcc 0xd 0x360088 >;   /* in zephyr/dts/arm/st/l4/stm32l4_sai.dtsi:26 */
			dmas = < &dma2 0x2 0x1 0x22800 >; /* in zephyr/dts/arm/st/l4/stm32l4_sai.dtsi:28 */
			status = "disabled";              /* in zephyr/dts/arm/st/l4/stm32l4_sai.dtsi:30 */
		};

		/* node '/soc/serial@40004800' defined in zephyr/dts/arm/st/l4/stm32l4p5.dtsi:110 */
		usart3: serial@40004800 {
			compatible = "st,stm32-usart",
			             "st,stm32-uart";                    /* in zephyr/dts/arm/st/l4/stm32l4p5.dtsi:111 */
			reg = < 0x40004800 0x400 >;                      /* in zephyr/dts/arm/st/l4/stm32l4p5.dtsi:112 */
			clocks = < &rcc 0x58 0x40000 >;                  /* in zephyr/dts/arm/st/l4/stm32l4p5.dtsi:113 */
			resets = < &rctl 0x712 >;                        /* in zephyr/dts/arm/st/l4/stm32l4p5.dtsi:114 */
			interrupts = < 0x27 0x0 >;                       /* in zephyr/dts/arm/st/l4/stm32l4p5.dtsi:115 */
			pinctrl-0 = < &usart3_tx_pb10 &usart3_rx_pb11 >; /* in zephyr/boards/blues/swan_r5/swan_r5.dts:109 */
			pinctrl-names = "default";                       /* in zephyr/boards/blues/swan_r5/swan_r5.dts:110 */
			current-speed = < 0x1c200 >;                     /* in zephyr/boards/blues/swan_r5/swan_r5.dts:111 */
			status = "okay";                                 /* in zephyr/boards/blues/swan_r5/swan_r5.dts:112 */
		};

		/* node '/soc/serial@40004c00' defined in zephyr/dts/arm/st/l4/stm32l4p5.dtsi:119 */
		uart4: serial@40004c00 {
			compatible = "st,stm32-uart";   /* in zephyr/dts/arm/st/l4/stm32l4p5.dtsi:120 */
			reg = < 0x40004c00 0x400 >;     /* in zephyr/dts/arm/st/l4/stm32l4p5.dtsi:121 */
			clocks = < &rcc 0x58 0x80000 >; /* in zephyr/dts/arm/st/l4/stm32l4p5.dtsi:122 */
			resets = < &rctl 0x713 >;       /* in zephyr/dts/arm/st/l4/stm32l4p5.dtsi:123 */
			interrupts = < 0x34 0x0 >;      /* in zephyr/dts/arm/st/l4/stm32l4p5.dtsi:124 */
			status = "disabled";            /* in zephyr/dts/arm/st/l4/stm32l4p5.dtsi:125 */
		};

		/* node '/soc/serial@40005000' defined in zephyr/dts/arm/st/l4/stm32l4p5.dtsi:128 */
		uart5: serial@40005000 {
			compatible = "st,stm32-uart";    /* in zephyr/dts/arm/st/l4/stm32l4p5.dtsi:129 */
			reg = < 0x40005000 0x400 >;      /* in zephyr/dts/arm/st/l4/stm32l4p5.dtsi:130 */
			clocks = < &rcc 0x58 0x100000 >; /* in zephyr/dts/arm/st/l4/stm32l4p5.dtsi:131 */
			resets = < &rctl 0x714 >;        /* in zephyr/dts/arm/st/l4/stm32l4p5.dtsi:132 */
			interrupts = < 0x35 0x0 >;       /* in zephyr/dts/arm/st/l4/stm32l4p5.dtsi:133 */
			status = "disabled";             /* in zephyr/dts/arm/st/l4/stm32l4p5.dtsi:134 */
		};

		/* node '/soc/i2c@40005800' defined in zephyr/dts/arm/st/l4/stm32l4p5.dtsi:137 */
		i2c2: i2c@40005800 {
			compatible = "st,stm32-i2c-v2";              /* in zephyr/dts/arm/st/l4/stm32l4p5.dtsi:138 */
			clock-frequency = < 0x186a0 >;               /* in zephyr/dts/arm/st/l4/stm32l4p5.dtsi:139 */
			#address-cells = < 0x1 >;                    /* in zephyr/dts/arm/st/l4/stm32l4p5.dtsi:140 */
			#size-cells = < 0x0 >;                       /* in zephyr/dts/arm/st/l4/stm32l4p5.dtsi:141 */
			reg = < 0x40005800 0x400 >;                  /* in zephyr/dts/arm/st/l4/stm32l4p5.dtsi:142 */
			clocks = < &rcc 0x58 0x400000 >;             /* in zephyr/dts/arm/st/l4/stm32l4p5.dtsi:143 */
			interrupts = < 0x21 0x0 >,
			             < 0x22 0x0 >;                   /* in zephyr/dts/arm/st/l4/stm32l4p5.dtsi:144 */
			interrupt-names = "event",
			                  "error";                   /* in zephyr/dts/arm/st/l4/stm32l4p5.dtsi:145 */
			pinctrl-0 = < &i2c2_scl_pf1 &i2c2_sda_pf0 >; /* in zephyr/boards/blues/swan_r5/swan_r5.dts:129 */
			pinctrl-names = "default";                   /* in zephyr/boards/blues/swan_r5/swan_r5.dts:130 */
			status = "okay";                             /* in zephyr/boards/blues/swan_r5/swan_r5.dts:131 */
			phandle = < 0x30 >;                          /* in zephyr/dts/arm/st/l4/stm32l4p5.dtsi:461 */
		};

		/* node '/soc/i2c@40008400' defined in zephyr/dts/arm/st/l4/stm32l4p5.dtsi:149 */
		i2c4: i2c@40008400 {
			compatible = "st,stm32-i2c-v2"; /* in zephyr/dts/arm/st/l4/stm32l4p5.dtsi:150 */
			clock-frequency = < 0x186a0 >;  /* in zephyr/dts/arm/st/l4/stm32l4p5.dtsi:151 */
			#address-cells = < 0x1 >;       /* in zephyr/dts/arm/st/l4/stm32l4p5.dtsi:152 */
			#size-cells = < 0x0 >;          /* in zephyr/dts/arm/st/l4/stm32l4p5.dtsi:153 */
			reg = < 0x40008400 0x400 >;     /* in zephyr/dts/arm/st/l4/stm32l4p5.dtsi:154 */
			clocks = < &rcc 0x5c 0x2 >;     /* in zephyr/dts/arm/st/l4/stm32l4p5.dtsi:155 */
			interrupts = < 0x54 0x0 >,
			             < 0x53 0x0 >;      /* in zephyr/dts/arm/st/l4/stm32l4p5.dtsi:156 */
			interrupt-names = "event",
			                  "error";      /* in zephyr/dts/arm/st/l4/stm32l4p5.dtsi:157 */
			status = "disabled";            /* in zephyr/dts/arm/st/l4/stm32l4p5.dtsi:158 */
			phandle = < 0x31 >;             /* in zephyr/dts/arm/st/l4/stm32l4p5.dtsi:469 */
		};

		/* node '/soc/spi@40003800' defined in zephyr/dts/arm/st/l4/stm32l4p5.dtsi:161 */
		spi2: spi@40003800 {
			compatible = "st,stm32-spi-fifo",
			             "st,stm32-spi";                                                 /* in zephyr/dts/arm/st/l4/stm32l4p5.dtsi:162 */
			#address-cells = < 0x1 >;                                                    /* in zephyr/dts/arm/st/l4/stm32l4p5.dtsi:163 */
			#size-cells = < 0x0 >;                                                       /* in zephyr/dts/arm/st/l4/stm32l4p5.dtsi:164 */
			reg = < 0x40003800 0x400 >;                                                  /* in zephyr/dts/arm/st/l4/stm32l4p5.dtsi:165 */
			clocks = < &rcc 0x58 0x4000 >;                                               /* in zephyr/dts/arm/st/l4/stm32l4p5.dtsi:166 */
			interrupts = < 0x24 0x5 >;                                                   /* in zephyr/dts/arm/st/l4/stm32l4p5.dtsi:167 */
			pinctrl-0 = < &spi2_nss_pd0 &spi2_sck_pd1 &spi2_miso_pb14 &spi2_mosi_pb15 >; /* in zephyr/boards/blues/swan_r5/swan_r5.dts:148 */
			pinctrl-names = "default";                                                   /* in zephyr/boards/blues/swan_r5/swan_r5.dts:150 */
			status = "okay";                                                             /* in zephyr/boards/blues/swan_r5/swan_r5.dts:151 */
		};

		/* node '/soc/spi@40003c00' defined in zephyr/dts/arm/st/l4/stm32l4p5.dtsi:171 */
		spi3: spi@40003c00 {
			compatible = "st,stm32-spi-fifo",
			             "st,stm32-spi";                                                   /* in zephyr/dts/arm/st/l4/stm32l4p5.dtsi:172 */
			#address-cells = < 0x1 >;                                                      /* in zephyr/dts/arm/st/l4/stm32l4p5.dtsi:173 */
			#size-cells = < 0x0 >;                                                         /* in zephyr/dts/arm/st/l4/stm32l4p5.dtsi:174 */
			reg = < 0x40003c00 0x400 >;                                                    /* in zephyr/dts/arm/st/l4/stm32l4p5.dtsi:175 */
			clocks = < &rcc 0x58 0x8000 >;                                                 /* in zephyr/dts/arm/st/l4/stm32l4p5.dtsi:176 */
			interrupts = < 0x33 0x5 >;                                                     /* in zephyr/dts/arm/st/l4/stm32l4p5.dtsi:177 */
			pinctrl-0 = < &spi3_nss_pa15 &spi3_sck_pc10 &spi3_miso_pc11 &spi3_mosi_pc12 >; /* in zephyr/boards/blues/swan_r5/swan_r5.dts:155 */
			pinctrl-names = "default";                                                     /* in zephyr/boards/blues/swan_r5/swan_r5.dts:157 */
			status = "okay";                                                               /* in zephyr/boards/blues/swan_r5/swan_r5.dts:158 */
		};

		/* node '/soc/timers@40000400' defined in zephyr/dts/arm/st/l4/stm32l4p5.dtsi:181 */
		timers3: timers@40000400 {
			compatible = "st,stm32-timers"; /* in zephyr/dts/arm/st/l4/stm32l4p5.dtsi:182 */
			reg = < 0x40000400 0x400 >;     /* in zephyr/dts/arm/st/l4/stm32l4p5.dtsi:183 */
			clocks = < &rcc 0x58 0x2 >,
			         < &rcc 0x8 0xff >;     /* in zephyr/dts/arm/st/l4/stm32l4p5.dtsi:184 */
			resets = < &rctl 0x701 >;       /* in zephyr/dts/arm/st/l4/stm32l4p5.dtsi:186 */
			interrupts = < 0x1d 0x0 >;      /* in zephyr/dts/arm/st/l4/stm32l4p5.dtsi:187 */
			interrupt-names = "global";     /* in zephyr/dts/arm/st/l4/stm32l4p5.dtsi:188 */
			st,prescaler = < 0x0 >;         /* in zephyr/dts/arm/st/l4/stm32l4p5.dtsi:189 */
			status = "disabled";            /* in zephyr/dts/arm/st/l4/stm32l4p5.dtsi:190 */

			/* node '/soc/timers@40000400/pwm' defined in zephyr/dts/arm/st/l4/stm32l4p5.dtsi:192 */
			pwm {
				compatible = "st,stm32-pwm"; /* in zephyr/dts/arm/st/l4/stm32l4p5.dtsi:193 */
				status = "disabled";         /* in zephyr/dts/arm/st/l4/stm32l4p5.dtsi:194 */
				#pwm-cells = < 0x3 >;        /* in zephyr/dts/arm/st/l4/stm32l4p5.dtsi:195 */
			};

			/* node '/soc/timers@40000400/counter' defined in zephyr/dts/arm/st/l4/stm32l4p5.dtsi:198 */
			counter {
				compatible = "st,stm32-counter"; /* in zephyr/dts/arm/st/l4/stm32l4p5.dtsi:199 */
				status = "disabled";             /* in zephyr/dts/arm/st/l4/stm32l4p5.dtsi:200 */
			};

			/* node '/soc/timers@40000400/qdec' defined in zephyr/dts/arm/st/l4/stm32l4p5.dtsi:203 */
			qdec {
				compatible = "st,stm32-qdec";    /* in zephyr/dts/arm/st/l4/stm32l4p5.dtsi:204 */
				st,input-filter-level = < 0x0 >; /* in zephyr/dts/arm/st/l4/stm32l4p5.dtsi:205 */
				status = "disabled";             /* in zephyr/dts/arm/st/l4/stm32l4p5.dtsi:206 */
			};
		};

		/* node '/soc/timers@40000800' defined in zephyr/dts/arm/st/l4/stm32l4p5.dtsi:210 */
		timers4: timers@40000800 {
			compatible = "st,stm32-timers"; /* in zephyr/dts/arm/st/l4/stm32l4p5.dtsi:211 */
			reg = < 0x40000800 0x400 >;     /* in zephyr/dts/arm/st/l4/stm32l4p5.dtsi:212 */
			clocks = < &rcc 0x58 0x4 >,
			         < &rcc 0x8 0xff >;     /* in zephyr/dts/arm/st/l4/stm32l4p5.dtsi:213 */
			resets = < &rctl 0x702 >;       /* in zephyr/dts/arm/st/l4/stm32l4p5.dtsi:215 */
			interrupts = < 0x1e 0x0 >;      /* in zephyr/dts/arm/st/l4/stm32l4p5.dtsi:216 */
			interrupt-names = "global";     /* in zephyr/dts/arm/st/l4/stm32l4p5.dtsi:217 */
			st,prescaler = < 0x0 >;         /* in zephyr/dts/arm/st/l4/stm32l4p5.dtsi:218 */
			status = "disabled";            /* in zephyr/dts/arm/st/l4/stm32l4p5.dtsi:219 */

			/* node '/soc/timers@40000800/pwm' defined in zephyr/dts/arm/st/l4/stm32l4p5.dtsi:221 */
			pwm {
				compatible = "st,stm32-pwm"; /* in zephyr/dts/arm/st/l4/stm32l4p5.dtsi:222 */
				status = "disabled";         /* in zephyr/dts/arm/st/l4/stm32l4p5.dtsi:223 */
				#pwm-cells = < 0x3 >;        /* in zephyr/dts/arm/st/l4/stm32l4p5.dtsi:224 */
			};

			/* node '/soc/timers@40000800/counter' defined in zephyr/dts/arm/st/l4/stm32l4p5.dtsi:227 */
			counter {
				compatible = "st,stm32-counter"; /* in zephyr/dts/arm/st/l4/stm32l4p5.dtsi:228 */
				status = "disabled";             /* in zephyr/dts/arm/st/l4/stm32l4p5.dtsi:229 */
			};

			/* node '/soc/timers@40000800/qdec' defined in zephyr/dts/arm/st/l4/stm32l4p5.dtsi:232 */
			qdec {
				compatible = "st,stm32-qdec";    /* in zephyr/dts/arm/st/l4/stm32l4p5.dtsi:233 */
				st,input-filter-level = < 0x0 >; /* in zephyr/dts/arm/st/l4/stm32l4p5.dtsi:234 */
				status = "disabled";             /* in zephyr/dts/arm/st/l4/stm32l4p5.dtsi:235 */
			};
		};

		/* node '/soc/timers@40000c00' defined in zephyr/dts/arm/st/l4/stm32l4p5.dtsi:239 */
		timers5: timers@40000c00 {
			compatible = "st,stm32-timers"; /* in zephyr/dts/arm/st/l4/stm32l4p5.dtsi:240 */
			reg = < 0x40000c00 0x400 >;     /* in zephyr/dts/arm/st/l4/stm32l4p5.dtsi:241 */
			clocks = < &rcc 0x58 0x8 >,
			         < &rcc 0x8 0xff >;     /* in zephyr/dts/arm/st/l4/stm32l4p5.dtsi:242 */
			resets = < &rctl 0x703 >;       /* in zephyr/dts/arm/st/l4/stm32l4p5.dtsi:244 */
			interrupts = < 0x32 0x0 >;      /* in zephyr/dts/arm/st/l4/stm32l4p5.dtsi:245 */
			interrupt-names = "global";     /* in zephyr/dts/arm/st/l4/stm32l4p5.dtsi:246 */
			st,prescaler = < 0x0 >;         /* in zephyr/dts/arm/st/l4/stm32l4p5.dtsi:247 */
			status = "disabled";            /* in zephyr/dts/arm/st/l4/stm32l4p5.dtsi:248 */

			/* node '/soc/timers@40000c00/pwm' defined in zephyr/dts/arm/st/l4/stm32l4p5.dtsi:250 */
			pwm {
				compatible = "st,stm32-pwm"; /* in zephyr/dts/arm/st/l4/stm32l4p5.dtsi:251 */
				status = "disabled";         /* in zephyr/dts/arm/st/l4/stm32l4p5.dtsi:252 */
				#pwm-cells = < 0x3 >;        /* in zephyr/dts/arm/st/l4/stm32l4p5.dtsi:253 */
			};

			/* node '/soc/timers@40000c00/counter' defined in zephyr/dts/arm/st/l4/stm32l4p5.dtsi:256 */
			counter {
				compatible = "st,stm32-counter"; /* in zephyr/dts/arm/st/l4/stm32l4p5.dtsi:257 */
				status = "disabled";             /* in zephyr/dts/arm/st/l4/stm32l4p5.dtsi:258 */
			};

			/* node '/soc/timers@40000c00/qdec' defined in zephyr/dts/arm/st/l4/stm32l4p5.dtsi:261 */
			qdec {
				compatible = "st,stm32-qdec";    /* in zephyr/dts/arm/st/l4/stm32l4p5.dtsi:262 */
				st,input-filter-level = < 0x0 >; /* in zephyr/dts/arm/st/l4/stm32l4p5.dtsi:263 */
				status = "disabled";             /* in zephyr/dts/arm/st/l4/stm32l4p5.dtsi:264 */
			};
		};

		/* node '/soc/timers@40001400' defined in zephyr/dts/arm/st/l4/stm32l4p5.dtsi:268 */
		timers7: timers@40001400 {
			compatible = "st,stm32-timers"; /* in zephyr/dts/arm/st/l4/stm32l4p5.dtsi:269 */
			reg = < 0x40001400 0x400 >;     /* in zephyr/dts/arm/st/l4/stm32l4p5.dtsi:270 */
			clocks = < &rcc 0x58 0x20 >,
			         < &rcc 0x8 0xff >;     /* in zephyr/dts/arm/st/l4/stm32l4p5.dtsi:271 */
			resets = < &rctl 0x705 >;       /* in zephyr/dts/arm/st/l4/stm32l4p5.dtsi:273 */
			interrupts = < 0x37 0x0 >;      /* in zephyr/dts/arm/st/l4/stm32l4p5.dtsi:274 */
			interrupt-names = "global";     /* in zephyr/dts/arm/st/l4/stm32l4p5.dtsi:275 */
			st,prescaler = < 0x0 >;         /* in zephyr/dts/arm/st/l4/stm32l4p5.dtsi:276 */
			status = "disabled";            /* in zephyr/dts/arm/st/l4/stm32l4p5.dtsi:277 */

			/* node '/soc/timers@40001400/pwm' defined in zephyr/dts/arm/st/l4/stm32l4p5.dtsi:279 */
			pwm {
				compatible = "st,stm32-pwm"; /* in zephyr/dts/arm/st/l4/stm32l4p5.dtsi:280 */
				status = "disabled";         /* in zephyr/dts/arm/st/l4/stm32l4p5.dtsi:281 */
				#pwm-cells = < 0x3 >;        /* in zephyr/dts/arm/st/l4/stm32l4p5.dtsi:282 */
			};

			/* node '/soc/timers@40001400/counter' defined in zephyr/dts/arm/st/l4/stm32l4p5.dtsi:285 */
			counter {
				compatible = "st,stm32-counter"; /* in zephyr/dts/arm/st/l4/stm32l4p5.dtsi:286 */
				status = "disabled";             /* in zephyr/dts/arm/st/l4/stm32l4p5.dtsi:287 */
			};
		};

		/* node '/soc/timers@40013400' defined in zephyr/dts/arm/st/l4/stm32l4p5.dtsi:291 */
		timers8: timers@40013400 {
			compatible = "st,stm32-timers"; /* in zephyr/dts/arm/st/l4/stm32l4p5.dtsi:292 */
			reg = < 0x40013400 0x400 >;     /* in zephyr/dts/arm/st/l4/stm32l4p5.dtsi:293 */
			clocks = < &rcc 0x60 0x2000 >,
			         < &rcc 0x9 0xff >;     /* in zephyr/dts/arm/st/l4/stm32l4p5.dtsi:294 */
			resets = < &rctl 0x80d >;       /* in zephyr/dts/arm/st/l4/stm32l4p5.dtsi:296 */
			interrupts = < 0x2b 0x0 >,
			             < 0x2c 0x0 >,
			             < 0x2d 0x0 >,
			             < 0x2e 0x0 >;      /* in zephyr/dts/arm/st/l4/stm32l4p5.dtsi:297 */
			interrupt-names = "brk",
			                  "up",
			                  "trgcom",
			                  "cc";         /* in zephyr/dts/arm/st/l4/stm32l4p5.dtsi:298 */
			st,prescaler = < 0x0 >;         /* in zephyr/dts/arm/st/l4/stm32l4p5.dtsi:299 */
			status = "disabled";            /* in zephyr/dts/arm/st/l4/stm32l4p5.dtsi:300 */

			/* node '/soc/timers@40013400/pwm' defined in zephyr/dts/arm/st/l4/stm32l4p5.dtsi:302 */
			pwm {
				compatible = "st,stm32-pwm"; /* in zephyr/dts/arm/st/l4/stm32l4p5.dtsi:303 */
				status = "disabled";         /* in zephyr/dts/arm/st/l4/stm32l4p5.dtsi:304 */
				#pwm-cells = < 0x3 >;        /* in zephyr/dts/arm/st/l4/stm32l4p5.dtsi:305 */
			};

			/* node '/soc/timers@40013400/qdec' defined in zephyr/dts/arm/st/l4/stm32l4p5.dtsi:308 */
			qdec {
				compatible = "st,stm32-qdec";    /* in zephyr/dts/arm/st/l4/stm32l4p5.dtsi:309 */
				st,input-filter-level = < 0x0 >; /* in zephyr/dts/arm/st/l4/stm32l4p5.dtsi:310 */
				status = "disabled";             /* in zephyr/dts/arm/st/l4/stm32l4p5.dtsi:311 */
			};
		};

		/* node '/soc/timers@40014800' defined in zephyr/dts/arm/st/l4/stm32l4p5.dtsi:315 */
		timers17: timers@40014800 {
			compatible = "st,stm32-timers"; /* in zephyr/dts/arm/st/l4/stm32l4p5.dtsi:316 */
			reg = < 0x40014800 0x400 >;     /* in zephyr/dts/arm/st/l4/stm32l4p5.dtsi:317 */
			clocks = < &rcc 0x60 0x40000 >,
			         < &rcc 0x9 0xff >;     /* in zephyr/dts/arm/st/l4/stm32l4p5.dtsi:318 */
			resets = < &rctl 0x812 >;       /* in zephyr/dts/arm/st/l4/stm32l4p5.dtsi:320 */
			interrupts = < 0x1a 0x0 >;      /* in zephyr/dts/arm/st/l4/stm32l4p5.dtsi:321 */
			interrupt-names = "global";     /* in zephyr/dts/arm/st/l4/stm32l4p5.dtsi:322 */
			st,prescaler = < 0x0 >;         /* in zephyr/dts/arm/st/l4/stm32l4p5.dtsi:323 */
			status = "disabled";            /* in zephyr/dts/arm/st/l4/stm32l4p5.dtsi:324 */

			/* node '/soc/timers@40014800/pwm' defined in zephyr/dts/arm/st/l4/stm32l4p5.dtsi:326 */
			pwm {
				compatible = "st,stm32-pwm"; /* in zephyr/dts/arm/st/l4/stm32l4p5.dtsi:327 */
				status = "disabled";         /* in zephyr/dts/arm/st/l4/stm32l4p5.dtsi:328 */
				#pwm-cells = < 0x3 >;        /* in zephyr/dts/arm/st/l4/stm32l4p5.dtsi:329 */
			};

			/* node '/soc/timers@40014800/counter' defined in zephyr/dts/arm/st/l4/stm32l4p5.dtsi:332 */
			counter {
				compatible = "st,stm32-counter"; /* in zephyr/dts/arm/st/l4/stm32l4p5.dtsi:333 */
				status = "disabled";             /* in zephyr/dts/arm/st/l4/stm32l4p5.dtsi:334 */
			};
		};

		/* node '/soc/can@40006400' defined in zephyr/dts/arm/st/l4/stm32l4p5.dtsi:338 */
		can1: can@40006400 {
			compatible = "st,stm32-bxcan";    /* in zephyr/dts/arm/st/l4/stm32l4p5.dtsi:339 */
			reg = < 0x40006400 0x400 >;       /* in zephyr/dts/arm/st/l4/stm32l4p5.dtsi:340 */
			interrupts = < 0x13 0x0 >,
			             < 0x14 0x0 >,
			             < 0x15 0x0 >,
			             < 0x16 0x0 >;        /* in zephyr/dts/arm/st/l4/stm32l4p5.dtsi:341 */
			interrupt-names = "TX",
			                  "RX0",
			                  "RX1",
			                  "SCE";          /* in zephyr/dts/arm/st/l4/stm32l4p5.dtsi:342 */
			clocks = < &rcc 0x58 0x2000000 >; /* in zephyr/dts/arm/st/l4/stm32l4p5.dtsi:343 */
			status = "disabled";              /* in zephyr/dts/arm/st/l4/stm32l4p5.dtsi:344 */
		};

		/* node '/soc/otgfs@50000000' defined in zephyr/dts/arm/st/l4/stm32l4p5.dtsi:347 */
		usbotg_fs: zephyr_udc0: otgfs@50000000 {
			compatible = "st,stm32-otgfs";                                               /* in zephyr/dts/arm/st/l4/stm32l4p5.dtsi:348 */
			reg = < 0x50000000 0x40000 >;                                                /* in zephyr/dts/arm/st/l4/stm32l4p5.dtsi:349 */
			interrupts = < 0x43 0x0 >;                                                   /* in zephyr/dts/arm/st/l4/stm32l4p5.dtsi:350 */
			interrupt-names = "otgfs";                                                   /* in zephyr/dts/arm/st/l4/stm32l4p5.dtsi:351 */
			num-bidir-endpoints = < 0x6 >;                                               /* in zephyr/dts/arm/st/l4/stm32l4p5.dtsi:352 */
			ram-size = < 0x500 >;                                                        /* in zephyr/dts/arm/st/l4/stm32l4p5.dtsi:353 */
			maximum-speed = "full-speed";                                                /* in zephyr/dts/arm/st/l4/stm32l4p5.dtsi:354 */
			clocks = < &rcc 0x4c 0x1000 >,
			         < &rcc 0x5 0x3a0088 >;                                              /* in zephyr/dts/arm/st/l4/stm32l4p5.dtsi:355 */
			phys = < &otgfs_phy >;                                                       /* in zephyr/dts/arm/st/l4/stm32l4p5.dtsi:357 */
			pinctrl-0 = < &usb_otg_fs_dm_pa11 &usb_otg_fs_dp_pa12 &usb_otg_fs_id_pa10 >; /* in zephyr/boards/blues/swan_r5/swan_r5.dts:162 */
			pinctrl-names = "default";                                                   /* in zephyr/boards/blues/swan_r5/swan_r5.dts:164 */
			status = "okay";                                                             /* in zephyr/boards/blues/swan_r5/swan_r5.dts:165 */
		};

		/* node '/soc/dmamux@40020800' defined in zephyr/dts/arm/st/l4/stm32l4p5.dtsi:369 */
		dmamux1: dmamux@40020800 {
			compatible = "st,stm32-dmamux"; /* in zephyr/dts/arm/st/l4/stm32l4p5.dtsi:370 */
			#dma-cells = < 0x3 >;           /* in zephyr/dts/arm/st/l4/stm32l4p5.dtsi:371 */
			reg = < 0x40020800 0x400 >;     /* in zephyr/dts/arm/st/l4/stm32l4p5.dtsi:372 */
			interrupts = < 0x5e 0x0 >;      /* in zephyr/dts/arm/st/l4/stm32l4p5.dtsi:373 */
			clocks = < &rcc 0x48 0x4 >;     /* in zephyr/dts/arm/st/l4/stm32l4p5.dtsi:374 */
			dma-channels = < 0xe >;         /* in zephyr/dts/arm/st/l4/stm32l4p5.dtsi:375 */
			dma-generators = < 0x4 >;       /* in zephyr/dts/arm/st/l4/stm32l4p5.dtsi:376 */
			dma-requests = < 0x59 >;        /* in zephyr/dts/arm/st/l4/stm32l4p5.dtsi:377 */
			status = "disabled";            /* in zephyr/dts/arm/st/l4/stm32l4p5.dtsi:378 */
		};

		/* node '/soc/dcmi@50050000' defined in zephyr/dts/arm/st/l4/stm32l4p5.dtsi:381 */
		dcmi: dcmi@50050000 {
			compatible = "st,stm32-dcmi";          /* in zephyr/dts/arm/st/l4/stm32l4p5.dtsi:382 */
			reg = < 0x50050000 0x400 >;            /* in zephyr/dts/arm/st/l4/stm32l4p5.dtsi:383 */
			interrupts = < 0x55 0x0 >;             /* in zephyr/dts/arm/st/l4/stm32l4p5.dtsi:384 */
			interrupt-names = "dcmi";              /* in zephyr/dts/arm/st/l4/stm32l4p5.dtsi:385 */
			clocks = < &rcc 0x4c 0x4000 >;         /* in zephyr/dts/arm/st/l4/stm32l4p5.dtsi:386 */
			status = "disabled";                   /* in zephyr/dts/arm/st/l4/stm32l4p5.dtsi:390 */
			dmas = < &dma1 0x1 0x5a 0x24480 0x0 >; /* in zephyr/dts/arm/st/l4/stm32l4r5.dtsi:40 */
		};

		/* node '/soc/sdmmc@50062400' defined in zephyr/dts/arm/st/l4/stm32l4p5.dtsi:393 */
		sdmmc1: sdmmc@50062400 {
			compatible = "st,stm32-sdmmc";   /* in zephyr/dts/arm/st/l4/stm32l4p5.dtsi:394 */
			reg = < 0x50062400 0x400 >;      /* in zephyr/dts/arm/st/l4/stm32l4p5.dtsi:395 */
			clocks = < &rcc 0x4c 0x400000 >,
			         < &rcc 0x5 0x3a0088 >;  /* in zephyr/dts/arm/st/l4/stm32l4p5.dtsi:396 */
			resets = < &rctl 0x596 >;        /* in zephyr/dts/arm/st/l4/stm32l4p5.dtsi:398 */
			interrupts = < 0x31 0x0 >;       /* in zephyr/dts/arm/st/l4/stm32l4p5.dtsi:399 */
			idma;                            /* in zephyr/dts/arm/st/l4/stm32l4p5.dtsi:400 */
			status = "disabled";             /* in zephyr/dts/arm/st/l4/stm32l4p5.dtsi:401 */
		};

		/* node '/soc/dac@40007400' defined in zephyr/dts/arm/st/l4/stm32l4p5.dtsi:415 */
		dac1: dac@40007400 {
			compatible = "st,stm32-dac";       /* in zephyr/dts/arm/st/l4/stm32l4p5.dtsi:416 */
			reg = < 0x40007400 0x400 >;        /* in zephyr/dts/arm/st/l4/stm32l4p5.dtsi:417 */
			clocks = < &rcc 0x58 0x20000000 >; /* in zephyr/dts/arm/st/l4/stm32l4p5.dtsi:418 */
			status = "disabled";               /* in zephyr/dts/arm/st/l4/stm32l4p5.dtsi:419 */
			#io-channel-cells = < 0x1 >;       /* in zephyr/dts/arm/st/l4/stm32l4p5.dtsi:420 */
		};

		/* node '/soc/spi@a0001000' defined in zephyr/dts/arm/st/l4/stm32l4p5.dtsi:423 */
		octospi1: spi@a0001000 {
			compatible = "st,stm32-ospi";    /* in zephyr/dts/arm/st/l4/stm32l4p5.dtsi:424 */
			reg = < 0xa0001000 0x400 >,
			      < 0x90000000 0x10000000 >; /* in zephyr/dts/arm/st/l4/stm32l4p5.dtsi:425 */
			interrupts = < 0x47 0x0 >;       /* in zephyr/dts/arm/st/l4/stm32l4p5.dtsi:426 */
			clock-names = "ospix",
			              "ospi-ker",
			              "ospi-mgr";        /* in zephyr/dts/arm/st/l4/stm32l4p5.dtsi:427 */
			clocks = < &rcc 0x50 0x100 >,
			         < &rcc 0x1 0x34009c >,
			         < &rcc 0x4c 0x100000 >; /* in zephyr/dts/arm/st/l4/stm32l4p5.dtsi:428 */
			#address-cells = < 0x1 >;        /* in zephyr/dts/arm/st/l4/stm32l4p5.dtsi:432 */
			#size-cells = < 0x0 >;           /* in zephyr/dts/arm/st/l4/stm32l4p5.dtsi:433 */
			status = "disabled";             /* in zephyr/dts/arm/st/l4/stm32l4p5.dtsi:434 */
		};

		/* node '/soc/spi@a0001400' defined in zephyr/dts/arm/st/l4/stm32l4p5.dtsi:437 */
		octospi2: spi@a0001400 {
			compatible = "st,stm32-ospi";    /* in zephyr/dts/arm/st/l4/stm32l4p5.dtsi:438 */
			reg = < 0xa0001400 0x400 >,
			      < 0x70000000 0x10000000 >; /* in zephyr/dts/arm/st/l4/stm32l4p5.dtsi:439 */
			interrupts = < 0x4c 0x0 >;       /* in zephyr/dts/arm/st/l4/stm32l4p5.dtsi:440 */
			clock-names = "ospix",
			              "ospi-ker",
			              "ospi-mgr";        /* in zephyr/dts/arm/st/l4/stm32l4p5.dtsi:441 */
			clocks = < &rcc 0x50 0x200 >,
			         < &rcc 0x1 0x34009c >,
			         < &rcc 0x4c 0x100000 >; /* in zephyr/dts/arm/st/l4/stm32l4p5.dtsi:442 */
			#address-cells = < 0x1 >;        /* in zephyr/dts/arm/st/l4/stm32l4p5.dtsi:446 */
			#size-cells = < 0x0 >;           /* in zephyr/dts/arm/st/l4/stm32l4p5.dtsi:447 */
			status = "disabled";             /* in zephyr/dts/arm/st/l4/stm32l4p5.dtsi:448 */
		};
	};

	/* node '/cpus' defined in zephyr/dts/arm/st/l4/stm32l4.dtsi:30 */
	cpus {
		#address-cells = < 0x1 >; /* in zephyr/dts/arm/st/l4/stm32l4.dtsi:31 */
		#size-cells = < 0x0 >;    /* in zephyr/dts/arm/st/l4/stm32l4.dtsi:32 */

		/* node '/cpus/cpu@0' defined in zephyr/dts/arm/st/l4/stm32l4.dtsi:34 */
		cpu0: cpu@0 {
			device_type = "cpu";                         /* in zephyr/dts/arm/st/l4/stm32l4.dtsi:35 */
			compatible = "arm,cortex-m4f";               /* in zephyr/dts/arm/st/l4/stm32l4.dtsi:36 */
			reg = < 0x0 >;                               /* in zephyr/dts/arm/st/l4/stm32l4.dtsi:37 */
			cpu-power-states = < &stop0 &stop1 &stop2 >; /* in zephyr/dts/arm/st/l4/stm32l4.dtsi:38 */
		};

		/* node '/cpus/power-states' defined in zephyr/dts/arm/st/l4/stm32l4.dtsi:41 */
		power-states {

			/* node '/cpus/power-states/state0' defined in zephyr/dts/arm/st/l4/stm32l4.dtsi:42 */
			stop0: state0 {
				compatible = "zephyr,power-state";    /* in zephyr/dts/arm/st/l4/stm32l4.dtsi:43 */
				power-state-name = "suspend-to-idle"; /* in zephyr/dts/arm/st/l4/stm32l4.dtsi:44 */
				substate-id = < 0x1 >;                /* in zephyr/dts/arm/st/l4/stm32l4.dtsi:45 */
				min-residency-us = < 0x1f4 >;         /* in zephyr/dts/arm/st/l4/stm32l4.dtsi:46 */
				phandle = < 0x29 >;                   /* in zephyr/dts/arm/st/l4/stm32l4.dtsi:38 */
			};

			/* node '/cpus/power-states/state1' defined in zephyr/dts/arm/st/l4/stm32l4.dtsi:49 */
			stop1: state1 {
				compatible = "zephyr,power-state";    /* in zephyr/dts/arm/st/l4/stm32l4.dtsi:50 */
				power-state-name = "suspend-to-idle"; /* in zephyr/dts/arm/st/l4/stm32l4.dtsi:51 */
				substate-id = < 0x2 >;                /* in zephyr/dts/arm/st/l4/stm32l4.dtsi:52 */
				min-residency-us = < 0x2bc >;         /* in zephyr/dts/arm/st/l4/stm32l4.dtsi:53 */
				phandle = < 0x2a >;                   /* in zephyr/dts/arm/st/l4/stm32l4.dtsi:38 */
			};

			/* node '/cpus/power-states/state2' defined in zephyr/dts/arm/st/l4/stm32l4.dtsi:56 */
			stop2: state2 {
				compatible = "zephyr,power-state";    /* in zephyr/dts/arm/st/l4/stm32l4.dtsi:57 */
				power-state-name = "suspend-to-idle"; /* in zephyr/dts/arm/st/l4/stm32l4.dtsi:58 */
				substate-id = < 0x3 >;                /* in zephyr/dts/arm/st/l4/stm32l4.dtsi:59 */
				min-residency-us = < 0x3e8 >;         /* in zephyr/dts/arm/st/l4/stm32l4.dtsi:60 */
				phandle = < 0x2b >;                   /* in zephyr/dts/arm/st/l4/stm32l4.dtsi:38 */
			};
		};
	};

	/* node '/memory@20000000' defined in zephyr/dts/arm/st/l4/stm32l4.dtsi:65 */
	sram0: memory@20000000 {
		compatible = "zephyr,memory-region",
		             "mmio-sram";            /* in zephyr/dts/arm/st/l4/stm32l4.dtsi:66 */
		zephyr,memory-region = "SRAM0";      /* in zephyr/dts/arm/st/l4/stm32l4.dtsi:67 */
		reg = < 0x20000000 0x30000 >;        /* in zephyr/dts/arm/st/l4/stm32l4r5.dtsi:15 */
	};

	/* node '/clocks' defined in zephyr/dts/arm/st/l4/stm32l4.dtsi:70 */
	clocks {

		/* node '/clocks/clk-hse' defined in zephyr/dts/arm/st/l4/stm32l4.dtsi:71 */
		clk_hse: clk-hse {
			#clock-cells = < 0x0 >;            /* in zephyr/dts/arm/st/l4/stm32l4.dtsi:72 */
			compatible = "st,stm32-hse-clock"; /* in zephyr/dts/arm/st/l4/stm32l4.dtsi:73 */
			status = "disabled";               /* in zephyr/dts/arm/st/l4/stm32l4.dtsi:74 */
		};

		/* node '/clocks/clk-hsi' defined in zephyr/dts/arm/st/l4/stm32l4.dtsi:77 */
		clk_hsi: clk-hsi {
			#clock-cells = < 0x0 >;         /* in zephyr/dts/arm/st/l4/stm32l4.dtsi:78 */
			compatible = "fixed-clock";     /* in zephyr/dts/arm/st/l4/stm32l4.dtsi:79 */
			clock-frequency = < 0xf42400 >; /* in zephyr/dts/arm/st/l4/stm32l4.dtsi:80 */
			status = "okay";                /* in zephyr/boards/blues/swan_r5/swan_r5.dts:73 */
			phandle = < 0x2c >;             /* in zephyr/boards/blues/swan_r5/swan_r5.dts:82 */
		};

		/* node '/clocks/clk-msi' defined in zephyr/dts/arm/st/l4/stm32l4.dtsi:84 */
		clk_msi: clk-msi {
			#clock-cells = < 0x0 >;            /* in zephyr/dts/arm/st/l4/stm32l4.dtsi:85 */
			compatible = "st,stm32-msi-clock"; /* in zephyr/dts/arm/st/l4/stm32l4.dtsi:86 */
			msi-range = < 0x6 >;               /* in zephyr/dts/arm/st/l4/stm32l4.dtsi:87 */
			status = "disabled";               /* in zephyr/dts/arm/st/l4/stm32l4.dtsi:88 */
		};

		/* node '/clocks/clk-lse' defined in zephyr/dts/arm/st/l4/stm32l4.dtsi:91 */
		clk_lse: clk-lse {
			#clock-cells = < 0x0 >;            /* in zephyr/dts/arm/st/l4/stm32l4.dtsi:92 */
			compatible = "st,stm32-lse-clock"; /* in zephyr/dts/arm/st/l4/stm32l4.dtsi:93 */
			clock-frequency = < 0x8000 >;      /* in zephyr/dts/arm/st/l4/stm32l4.dtsi:94 */
			driving-capability = < 0x0 >;      /* in zephyr/dts/arm/st/l4/stm32l4.dtsi:95 */
			status = "disabled";               /* in zephyr/dts/arm/st/l4/stm32l4.dtsi:96 */
		};

		/* node '/clocks/clk-lsi' defined in zephyr/dts/arm/st/l4/stm32l4.dtsi:99 */
		clk_lsi: clk-lsi {
			#clock-cells = < 0x0 >;       /* in zephyr/dts/arm/st/l4/stm32l4.dtsi:100 */
			compatible = "fixed-clock";   /* in zephyr/dts/arm/st/l4/stm32l4.dtsi:101 */
			clock-frequency = < 0x7d00 >; /* in zephyr/dts/arm/st/l4/stm32l4.dtsi:102 */
			status = "okay";              /* in zephyr/boards/blues/swan_r5/swan_r5.dts:65 */
		};

		/* node '/clocks/pll' defined in zephyr/dts/arm/st/l4/stm32l4.dtsi:106 */
		pll: pll {
			#clock-cells = < 0x0 >;              /* in zephyr/dts/arm/st/l4/stm32l4.dtsi:107 */
			compatible = "st,stm32l4-pll-clock"; /* in zephyr/dts/arm/st/l4/stm32l4.dtsi:108 */
			div-m = < 0x4 >;                     /* in zephyr/boards/blues/swan_r5/swan_r5.dts:77 */
			mul-n = < 0x28 >;                    /* in zephyr/boards/blues/swan_r5/swan_r5.dts:78 */
			div-p = < 0x7 >;                     /* in zephyr/boards/blues/swan_r5/swan_r5.dts:79 */
			div-q = < 0x2 >;                     /* in zephyr/boards/blues/swan_r5/swan_r5.dts:80 */
			div-r = < 0x2 >;                     /* in zephyr/boards/blues/swan_r5/swan_r5.dts:81 */
			clocks = < &clk_hsi >;               /* in zephyr/boards/blues/swan_r5/swan_r5.dts:82 */
			status = "okay";                     /* in zephyr/boards/blues/swan_r5/swan_r5.dts:83 */
			phandle = < 0x3 >;                   /* in zephyr/boards/blues/swan_r5/swan_r5.dts:87 */
		};

		/* node '/clocks/pllsai1' defined in zephyr/dts/arm/st/l4/stm32l4.dtsi:112 */
		pllsai1: pllsai1 {
			#clock-cells = < 0x0 >;                 /* in zephyr/dts/arm/st/l4/stm32l4.dtsi:113 */
			compatible = "st,stm32l4-pllsai-clock"; /* in zephyr/dts/arm/st/l4/stm32l4.dtsi:114 */
			status = "disabled";                    /* in zephyr/dts/arm/st/l4/stm32l4.dtsi:115 */
		};

		/* node '/clocks/clk-hsi48' defined in zephyr/dts/arm/st/l4/stm32l4p5.dtsi:34 */
		clk_hsi48: clk-hsi48 {
			#clock-cells = < 0x0 >;          /* in zephyr/dts/arm/st/l4/stm32l4p5.dtsi:35 */
			compatible = "fixed-clock";      /* in zephyr/dts/arm/st/l4/stm32l4p5.dtsi:36 */
			clock-frequency = < 0x2dc6c00 >; /* in zephyr/dts/arm/st/l4/stm32l4p5.dtsi:37 */
			status = "okay";                 /* in zephyr/boards/blues/swan_r5/swan_r5.dts:69 */
		};

		/* node '/clocks/pllsai2' defined in zephyr/dts/arm/st/l4/stm32l4p5.dtsi:41 */
		pllsai2: pllsai2 {
			#clock-cells = < 0x0 >;                 /* in zephyr/dts/arm/st/l4/stm32l4p5.dtsi:42 */
			compatible = "st,stm32l4-pllsai-clock"; /* in zephyr/dts/arm/st/l4/stm32l4p5.dtsi:43 */
			status = "disabled";                    /* in zephyr/dts/arm/st/l4/stm32l4p5.dtsi:44 */
		};
	};

	/* node '/mcos' defined in zephyr/dts/arm/st/l4/stm32l4.dtsi:119 */
	mcos {

		/* node '/mcos/mco1' defined in zephyr/dts/arm/st/l4/stm32l4.dtsi:120 */
		mco1: mco1 {
			compatible = "st,stm32-clock-mco"; /* in zephyr/dts/arm/st/l4/stm32l4.dtsi:121 */
			status = "disabled";               /* in zephyr/dts/arm/st/l4/stm32l4.dtsi:122 */
		};
	};

	/* node '/dietemp' defined in zephyr/dts/arm/st/l4/stm32l4.dtsi:552 */
	die_temp: dietemp {
		compatible = "st,stm32-temp-cal"; /* in zephyr/dts/arm/st/l4/stm32l4.dtsi:553 */
		ts-cal1-addr = < 0x1fff75a8 >;    /* in zephyr/dts/arm/st/l4/stm32l4.dtsi:554 */
		ts-cal2-addr = < 0x1fff75ca >;    /* in zephyr/dts/arm/st/l4/stm32l4.dtsi:555 */
		ts-cal1-temp = < 0x1e >;          /* in zephyr/dts/arm/st/l4/stm32l4.dtsi:556 */
		ts-cal2-temp = < 0x82 >;          /* in zephyr/dts/arm/st/l4/stm32l4.dtsi:557 */
		ts-cal-vrefanalog = < 0xbb8 >;    /* in zephyr/dts/arm/st/l4/stm32l4.dtsi:558 */
		io-channels = < &adc1 0x11 >;     /* in zephyr/dts/arm/st/l4/stm32l4.dtsi:559 */
		status = "disabled";              /* in zephyr/dts/arm/st/l4/stm32l4.dtsi:560 */
	};

	/* node '/vref' defined in zephyr/dts/arm/st/l4/stm32l4.dtsi:563 */
	vref: vref {
		compatible = "st,stm32-vref";      /* in zephyr/dts/arm/st/l4/stm32l4.dtsi:564 */
		vrefint-cal-addr = < 0x1fff75aa >; /* in zephyr/dts/arm/st/l4/stm32l4.dtsi:565 */
		vrefint-cal-mv = < 0xbb8 >;        /* in zephyr/dts/arm/st/l4/stm32l4.dtsi:566 */
		io-channels = < &adc1 0x0 >;       /* in zephyr/dts/arm/st/l4/stm32l4.dtsi:567 */
		status = "okay";                   /* in zephyr/boards/blues/swan_r5/swan_r5.dts:207 */
	};

	/* node '/vbat' defined in zephyr/dts/arm/st/l4/stm32l4.dtsi:571 */
	vbat: vbat {
		compatible = "st,stm32-vbat"; /* in zephyr/dts/arm/st/l4/stm32l4.dtsi:572 */
		ratio = < 0x3 >;              /* in zephyr/dts/arm/st/l4/stm32l4.dtsi:573 */
		io-channels = < &adc1 0x12 >; /* in zephyr/dts/arm/st/l4/stm32l4.dtsi:574 */
		status = "okay";              /* in zephyr/boards/blues/swan_r5/swan_r5.dts:211 */
	};

	/* node '/smbus1' defined in zephyr/dts/arm/st/l4/stm32l4.dtsi:578 */
	smbus1: smbus1 {
		compatible = "st,stm32-smbus"; /* in zephyr/dts/arm/st/l4/stm32l4.dtsi:579 */
		#address-cells = < 0x1 >;      /* in zephyr/dts/arm/st/l4/stm32l4.dtsi:580 */
		#size-cells = < 0x0 >;         /* in zephyr/dts/arm/st/l4/stm32l4.dtsi:581 */
		i2c = < &i2c1 >;               /* in zephyr/dts/arm/st/l4/stm32l4.dtsi:582 */
		status = "disabled";           /* in zephyr/dts/arm/st/l4/stm32l4.dtsi:583 */
	};

	/* node '/smbus3' defined in zephyr/dts/arm/st/l4/stm32l4.dtsi:586 */
	smbus3: smbus3 {
		compatible = "st,stm32-smbus"; /* in zephyr/dts/arm/st/l4/stm32l4.dtsi:587 */
		#address-cells = < 0x1 >;      /* in zephyr/dts/arm/st/l4/stm32l4.dtsi:588 */
		#size-cells = < 0x0 >;         /* in zephyr/dts/arm/st/l4/stm32l4.dtsi:589 */
		i2c = < &i2c3 >;               /* in zephyr/dts/arm/st/l4/stm32l4.dtsi:590 */
		status = "disabled";           /* in zephyr/dts/arm/st/l4/stm32l4.dtsi:591 */
	};

	/* node '/memory@10000000' defined in zephyr/dts/arm/st/l4/stm32l4p5.dtsi:21 */
	sram1: memory@10000000 {
		compatible = "zephyr,memory-region",
		             "mmio-sram";            /* in zephyr/dts/arm/st/l4/stm32l4p5.dtsi:22 */
		zephyr,memory-region = "SRAM1";      /* in zephyr/dts/arm/st/l4/stm32l4p5.dtsi:23 */
		reg = < 0x10000000 0x10000 >;        /* in zephyr/dts/arm/st/l4/stm32l4r5.dtsi:19 */
	};

	/* node '/otgfs_phy' defined in zephyr/dts/arm/st/l4/stm32l4p5.dtsi:452 */
	otgfs_phy: otgfs_phy {
		compatible = "usb-nop-xceiv"; /* in zephyr/dts/arm/st/l4/stm32l4p5.dtsi:453 */
		#phy-cells = < 0x0 >;         /* in zephyr/dts/arm/st/l4/stm32l4p5.dtsi:454 */
		phandle = < 0x24 >;           /* in zephyr/dts/arm/st/l4/stm32l4p5.dtsi:357 */
	};

	/* node '/smbus2' defined in zephyr/dts/arm/st/l4/stm32l4p5.dtsi:457 */
	smbus2: smbus2 {
		compatible = "st,stm32-smbus"; /* in zephyr/dts/arm/st/l4/stm32l4p5.dtsi:458 */
		#address-cells = < 0x1 >;      /* in zephyr/dts/arm/st/l4/stm32l4p5.dtsi:459 */
		#size-cells = < 0x0 >;         /* in zephyr/dts/arm/st/l4/stm32l4p5.dtsi:460 */
		i2c = < &i2c2 >;               /* in zephyr/dts/arm/st/l4/stm32l4p5.dtsi:461 */
		status = "disabled";           /* in zephyr/dts/arm/st/l4/stm32l4p5.dtsi:462 */
	};

	/* node '/smbus4' defined in zephyr/dts/arm/st/l4/stm32l4p5.dtsi:465 */
	smbus4: smbus4 {
		compatible = "st,stm32-smbus"; /* in zephyr/dts/arm/st/l4/stm32l4p5.dtsi:466 */
		#address-cells = < 0x1 >;      /* in zephyr/dts/arm/st/l4/stm32l4p5.dtsi:467 */
		#size-cells = < 0x0 >;         /* in zephyr/dts/arm/st/l4/stm32l4p5.dtsi:468 */
		i2c = < &i2c4 >;               /* in zephyr/dts/arm/st/l4/stm32l4p5.dtsi:469 */
		status = "disabled";           /* in zephyr/dts/arm/st/l4/stm32l4p5.dtsi:470 */
	};

	/* node '/memory@20040000' defined in zephyr/dts/arm/st/l4/stm32l4r5.dtsi:22 */
	sram2: memory@20040000 {
		compatible = "zephyr,memory-region",
		             "mmio-sram";            /* in zephyr/dts/arm/st/l4/stm32l4r5.dtsi:23 */
		zephyr,memory-region = "SRAM2";      /* in zephyr/dts/arm/st/l4/stm32l4r5.dtsi:24 */
		reg = < 0x20040000 0x60000 >;        /* in zephyr/dts/arm/st/l4/stm32l4r5.dtsi:25 */
	};

	/* node '/connector' defined in zephyr/boards/blues/swan_r5/feather_connector.dtsi:8 */
	feather_header: connector {
		compatible = "adafruit-feather-header";    /* in zephyr/boards/blues/swan_r5/feather_connector.dtsi:9 */
		#gpio-cells = < 0x2 >;                     /* in zephyr/boards/blues/swan_r5/feather_connector.dtsi:10 */
		gpio-map-mask = < 0xffffffff 0xffffffc0 >; /* in zephyr/boards/blues/swan_r5/feather_connector.dtsi:11 */
		gpio-map-pass-thru = < 0x0 0x3f >;         /* in zephyr/boards/blues/swan_r5/feather_connector.dtsi:12 */
		gpio-map = < 0x0 0x0 &gpioa 0x3 0x0 >,
		           < 0x1 0x0 &gpioa 0x1 0x0 >,
		           < 0x2 0x0 &gpioc 0x3 0x0 >,
		           < 0x3 0x0 &gpioc 0x1 0x0 >,
		           < 0x4 0x0 &gpioc 0x4 0x0 >,
		           < 0x5 0x0 &gpioc 0x5 0x0 >,
		           < 0x6 0x0 &gpioa 0x5 0x0 >,
		           < 0x7 0x0 &gpioa 0x7 0x0 >,
		           < 0x8 0x0 &gpioa 0x6 0x0 >,
		           < 0x9 0x0 &gpioa 0xa 0x0 >,
		           < 0xa 0x0 &gpioa 0x9 0x0 >,
		           < 0xb 0x0 &gpioe 0x3 0x0 >,
		           < 0xc 0x0 &gpiob 0x7 0x0 >,
		           < 0xd 0x0 &gpiob 0x6 0x0 >,
		           < 0xe 0x0 &gpioe 0xb 0x0 >,
		           < 0xf 0x0 &gpioe 0x9 0x0 >,
		           < 0x10 0x0 &gpiod 0xf 0x0 >,
		           < 0x11 0x0 &gpioa 0x4 0x0 >,
		           < 0x12 0x0 &gpioa 0x7 0x0 >,
		           < 0x13 0x0 &gpioa 0x6 0x0 >,
		           < 0x14 0x0 &gpioa 0x5 0x0 >;    /* in zephyr/boards/blues/swan_r5/feather_connector.dtsi:13 */
	};

	/* node '/leds' defined in zephyr/boards/blues/swan_r5/swan_r5.dts:24 */
	leds {
		compatible = "gpio-leds"; /* in zephyr/boards/blues/swan_r5/swan_r5.dts:25 */

		/* node '/leds/led_0' defined in zephyr/boards/blues/swan_r5/swan_r5.dts:27 */
		led0: led_0 {
			gpios = < &gpioe 0x2 0x0 >; /* in zephyr/boards/blues/swan_r5/swan_r5.dts:28 */
			label = "User LD1";         /* in zephyr/boards/blues/swan_r5/swan_r5.dts:29 */
		};
	};

	/* node '/gpio_keys' defined in zephyr/boards/blues/swan_r5/swan_r5.dts:33 */
	gpio_keys {
		compatible = "gpio-keys"; /* in zephyr/boards/blues/swan_r5/swan_r5.dts:34 */

		/* node '/gpio_keys/button' defined in zephyr/boards/blues/swan_r5/swan_r5.dts:36 */
		user_button: button {
			label = "User";             /* in zephyr/boards/blues/swan_r5/swan_r5.dts:37 */
			gpios = < &gpioc 0xd 0x0 >; /* in zephyr/boards/blues/swan_r5/swan_r5.dts:38 */
			zephyr,code = < 0xb >;      /* in zephyr/boards/blues/swan_r5/swan_r5.dts:39 */
		};
	};

	/* node '/zephyr,user' defined in zephyr/boards/blues/swan_r5/swan_r5.dts:44 */
	zephyr,user {
		dischrg-gpios = < &gpioe 0x6 0x7 >; /* in zephyr/boards/blues/swan_r5/swan_r5.dts:45 */
		status = "disabled";                /* in zephyr/boards/blues/swan_r5/swan_r5.dts:46 */
	};

	/* node '/supply-3v3' defined in zephyr/boards/blues/swan_r5/swan_r5.dts:49 */
	supply-3v3 {
		compatible = "regulator-fixed";    /* in zephyr/boards/blues/swan_r5/swan_r5.dts:50 */
		regulator-name = "supply-3v3";     /* in zephyr/boards/blues/swan_r5/swan_r5.dts:51 */
		enable-gpios = < &gpioe 0x4 0x0 >; /* in zephyr/boards/blues/swan_r5/swan_r5.dts:52 */
		regulator-boot-on;                 /* in zephyr/boards/blues/swan_r5/swan_r5.dts:53 */
	};
};
